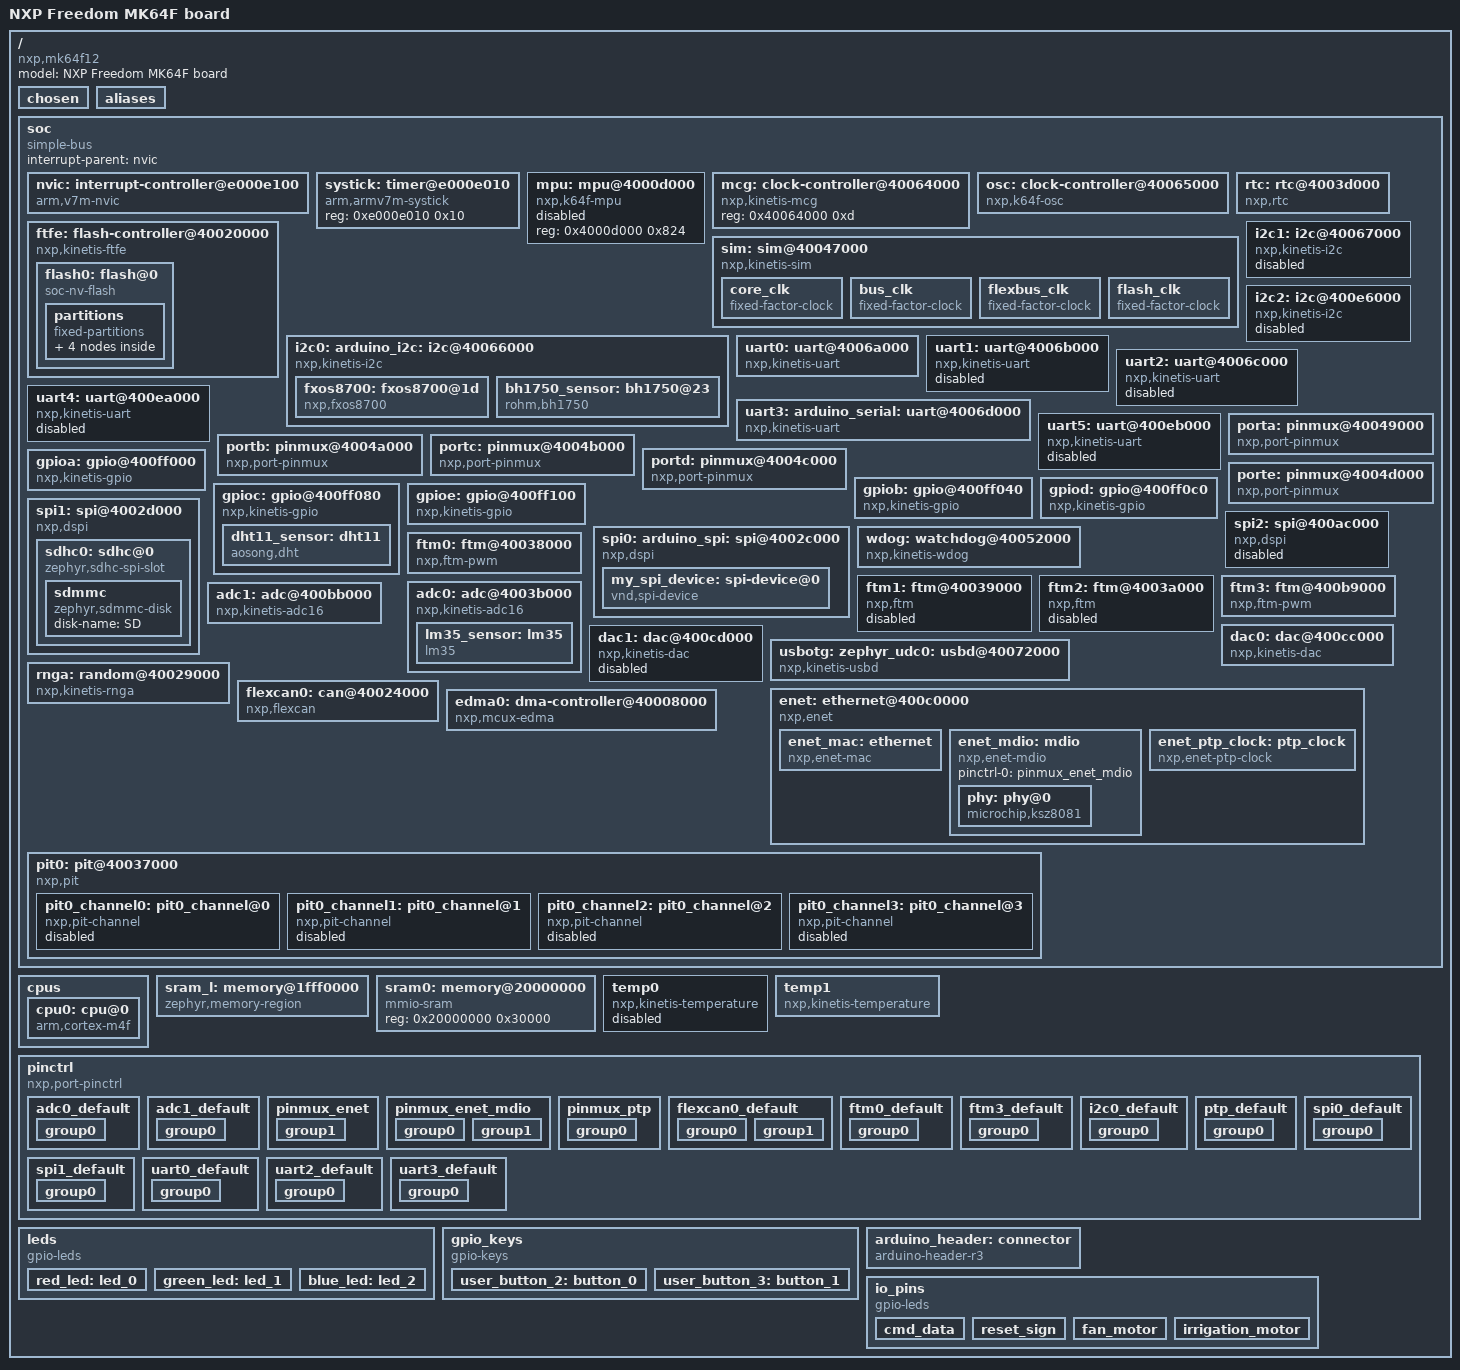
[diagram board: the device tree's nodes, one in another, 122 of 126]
/dts-v1/;

/* node '/' defined in zephyr\dts\common\skeleton.dtsi:9 */
/ {
	#address-cells = < 0x1 >;          /* in zephyr\dts\common\skeleton.dtsi:10 */
	#size-cells = < 0x1 >;             /* in zephyr\dts\common\skeleton.dtsi:11 */
	model = "NXP Freedom MK64F board"; /* in zephyr\boards\nxp\frdm_k64f\frdm_k64f.dts:10 */
	compatible = "nxp,mk64f12",
	             "nxp,k64f",
	             "nxp,k6x";            /* in zephyr\boards\nxp\frdm_k64f\frdm_k64f.dts:11 */

	/* node '/chosen' defined in zephyr\dts\common\skeleton.dtsi:12 */
	chosen {
		zephyr,entropy = &rnga;                   /* in zephyr\dts\arm\nxp\nxp_k6x.dtsi:17 */
		zephyr,flash-controller = &ftfe;          /* in zephyr\dts\arm\nxp\nxp_k6x.dtsi:18 */
		zephyr,sram = &sram0;                     /* in zephyr\boards\nxp\frdm_k64f\frdm_k64f.dts:25 */
		zephyr,flash = &flash0;                   /* in zephyr\boards\nxp\frdm_k64f\frdm_k64f.dts:26 */
		zephyr,code-partition = &slot0_partition; /* in zephyr\boards\nxp\frdm_k64f\frdm_k64f.dts:27 */
		zephyr,console = &uart0;                  /* in zephyr\boards\nxp\frdm_k64f\frdm_k64f.dts:28 */
		zephyr,shell-uart = &uart0;               /* in zephyr\boards\nxp\frdm_k64f\frdm_k64f.dts:29 */
		zephyr,uart-pipe = &uart0;                /* in zephyr\boards\nxp\frdm_k64f\frdm_k64f.dts:30 */
		zephyr,canbus = &flexcan0;                /* in zephyr\boards\nxp\frdm_k64f\frdm_k64f.dts:31 */
		zephyr,uart-mcumgr = &uart0;              /* in zephyr\boards\nxp\frdm_k64f\frdm_k64f.dts:32 */
	};

	/* node '/aliases' defined in zephyr\dts\common\skeleton.dtsi:13 */
	aliases {
		watchdog0 = &wdog;                       /* in zephyr\dts\arm\nxp\nxp_k6x.dtsi:13 */
		led0 = &green_led;                       /* in zephyr\boards\nxp\frdm_k64f\frdm_k64f.dts:14 */
		led1 = &blue_led;                        /* in zephyr\boards\nxp\frdm_k64f\frdm_k64f.dts:15 */
		led2 = &red_led;                         /* in zephyr\boards\nxp\frdm_k64f\frdm_k64f.dts:16 */
		sw0 = &user_button_3;                    /* in zephyr\boards\nxp\frdm_k64f\frdm_k64f.dts:17 */
		sw1 = &user_button_2;                    /* in zephyr\boards\nxp\frdm_k64f\frdm_k64f.dts:18 */
		magn0 = &fxos8700;                       /* in zephyr\boards\nxp\frdm_k64f\frdm_k64f.dts:19 */
		accel0 = &fxos8700;                      /* in zephyr\boards\nxp\frdm_k64f\frdm_k64f.dts:20 */
		mcuboot-button0 = &user_button_2;        /* in zephyr\boards\nxp\frdm_k64f\frdm_k64f.dts:21 */
		cmd-data = &cmd_data;                    /* in ..\nokia_lcd_zephyr\boards\frdm_k64f.overlay:4 */
		reset-pin = &reset_sign;                 /* in ..\nokia_lcd_zephyr\boards\frdm_k64f.overlay:5 */
		lm35 = &lm35_sensor;                     /* in ..\nokia_lcd_zephyr\boards\frdm_k64f.overlay:8 */
		bh1750 = &bh1750_sensor;                 /* in ..\nokia_lcd_zephyr\boards\frdm_k64f.overlay:9 */
		dht11 = &dht11_sensor;                   /* in ..\nokia_lcd_zephyr\boards\frdm_k64f.overlay:10 */
		fan-actuator = &fan_motor;               /* in ..\nokia_lcd_zephyr\boards\frdm_k64f.overlay:13 */
		irrigation-actuator = &irrigation_motor; /* in ..\nokia_lcd_zephyr\boards\frdm_k64f.overlay:14 */
	};

	/* node '/soc' defined in zephyr\dts\arm\armv7-m.dtsi:6 */
	soc {
		#address-cells = < 0x1 >;     /* in zephyr\dts\arm\armv7-m.dtsi:7 */
		#size-cells = < 0x1 >;        /* in zephyr\dts\arm\armv7-m.dtsi:8 */
		compatible = "simple-bus";    /* in zephyr\dts\arm\armv7-m.dtsi:9 */
		interrupt-parent = < &nvic >; /* in zephyr\dts\arm\armv7-m.dtsi:10 */
		ranges;                       /* in zephyr\dts\arm\armv7-m.dtsi:11 */

		/* node '/soc/interrupt-controller@e000e100' defined in zephyr\dts\arm\armv7-m.dtsi:13 */
		nvic: interrupt-controller@e000e100 {
			#address-cells = < 0x1 >;            /* in zephyr\dts\arm\armv7-m.dtsi:14 */
			compatible = "arm,v7m-nvic";         /* in zephyr\dts\arm\armv7-m.dtsi:15 */
			reg = < 0xe000e100 0xc00 >;          /* in zephyr\dts\arm\armv7-m.dtsi:16 */
			interrupt-controller;                /* in zephyr\dts\arm\armv7-m.dtsi:17 */
			#interrupt-cells = < 0x2 >;          /* in zephyr\dts\arm\armv7-m.dtsi:18 */
			arm,num-irq-priority-bits = < 0x4 >; /* in zephyr\dts\arm\nxp\nxp_k6x.dtsi:582 */
			phandle = < 0x1 >;                   /* in zephyr\dts\arm\armv7-m.dtsi:10 */
		};

		/* node '/soc/timer@e000e010' defined in zephyr\dts\arm\armv7-m.dtsi:21 */
		systick: timer@e000e010 {
			compatible = "arm,armv7m-systick"; /* in zephyr\dts\arm\armv7-m.dtsi:22 */
			reg = < 0xe000e010 0x10 >;         /* in zephyr\dts\arm\armv7-m.dtsi:23 */
		};

		/* node '/soc/mpu@4000d000' defined in zephyr\dts\arm\nxp\nxp_k6x.dtsi:83 */
		mpu: mpu@4000d000 {
			compatible = "nxp,k64f-mpu"; /* in zephyr\dts\arm\nxp\nxp_k6x.dtsi:84 */
			reg = < 0x4000d000 0x824 >;  /* in zephyr\dts\arm\nxp\nxp_k6x.dtsi:85 */
			status = "disabled";         /* in zephyr\dts\arm\nxp\nxp_k6x.dtsi:87 */
		};

		/* node '/soc/clock-controller@40064000' defined in zephyr\dts\arm\nxp\nxp_k6x.dtsi:90 */
		mcg: clock-controller@40064000 {
			compatible = "nxp,kinetis-mcg"; /* in zephyr\dts\arm\nxp\nxp_k6x.dtsi:91 */
			reg = < 0x40064000 0xd >;       /* in zephyr\dts\arm\nxp\nxp_k6x.dtsi:92 */
			#clock-cells = < 0x1 >;         /* in zephyr\dts\arm\nxp\nxp_k6x.dtsi:93 */
			phandle = < 0x2 >;              /* in zephyr\dts\arm\nxp\nxp_k6x.dtsi:119 */
		};

		/* node '/soc/clock-controller@40065000' defined in zephyr\dts\arm\nxp\nxp_k6x.dtsi:96 */
		osc: clock-controller@40065000 {
			compatible = "nxp,k64f-osc"; /* in zephyr\dts\arm\nxp\nxp_k6x.dtsi:97 */
			reg = < 0x40065000 0x4 >;    /* in zephyr\dts\arm\nxp\nxp_k6x.dtsi:98 */
			enable-external-reference;   /* in zephyr\dts\arm\nxp\nxp_k6x.dtsi:100 */
		};

		/* node '/soc/rtc@4003d000' defined in zephyr\dts\arm\nxp\nxp_k6x.dtsi:103 */
		rtc: rtc@4003d000 {
			compatible = "nxp,rtc";       /* in zephyr\dts\arm\nxp\nxp_k6x.dtsi:104 */
			reg = < 0x4003d000 0x1000 >;  /* in zephyr\dts\arm\nxp\nxp_k6x.dtsi:105 */
			interrupts = < 0x2e 0x0 >,
			             < 0x2f 0x0 >;    /* in zephyr\dts\arm\nxp\nxp_k6x.dtsi:106 */
			interrupt-names = "alarm",
			                  "seconds";  /* in zephyr\dts\arm\nxp\nxp_k6x.dtsi:107 */
			clock-frequency = < 0x8000 >; /* in zephyr\dts\arm\nxp\nxp_k6x.dtsi:108 */
			prescaler = < 0x8000 >;       /* in zephyr\dts\arm\nxp\nxp_k6x.dtsi:109 */
		};

		/* node '/soc/sim@40047000' defined in zephyr\dts\arm\nxp\nxp_k6x.dtsi:112 */
		sim: sim@40047000 {
			compatible = "nxp,kinetis-sim"; /* in zephyr\dts\arm\nxp\nxp_k6x.dtsi:113 */
			reg = < 0x40047000 0x1060 >;    /* in zephyr\dts\arm\nxp\nxp_k6x.dtsi:114 */
			#clock-cells = < 0x3 >;         /* in zephyr\dts\arm\nxp\nxp_k6x.dtsi:115 */
			pllfll-select = < 0x1 >;        /* in zephyr\boards\nxp\frdm_k64f\frdm_k64f.dts:99 */
			er32k-select = < 0x2 >;         /* in zephyr\boards\nxp\frdm_k64f\frdm_k64f.dts:100 */
			phandle = < 0x3 >;              /* in zephyr\dts\arm\nxp\nxp_k6x.dtsi:171 */

			/* node '/soc/sim@40047000/core_clk' defined in zephyr\dts\arm\nxp\nxp_k6x.dtsi:117 */
			core_clk {
				compatible = "fixed-factor-clock"; /* in zephyr\dts\arm\nxp\nxp_k6x.dtsi:118 */
				clocks = < &mcg 0x1 >;             /* in zephyr\dts\arm\nxp\nxp_k6x.dtsi:119 */
				clock-div = < 0x1 >;               /* in zephyr\dts\arm\nxp\nxp_k6x.dtsi:120 */
				#clock-cells = < 0x0 >;            /* in zephyr\dts\arm\nxp\nxp_k6x.dtsi:121 */
			};

			/* node '/soc/sim@40047000/bus_clk' defined in zephyr\dts\arm\nxp\nxp_k6x.dtsi:124 */
			bus_clk {
				compatible = "fixed-factor-clock"; /* in zephyr\dts\arm\nxp\nxp_k6x.dtsi:125 */
				clocks = < &mcg 0x1 >;             /* in zephyr\dts\arm\nxp\nxp_k6x.dtsi:126 */
				clock-div = < 0x2 >;               /* in zephyr\dts\arm\nxp\nxp_k6x.dtsi:127 */
				#clock-cells = < 0x0 >;            /* in zephyr\dts\arm\nxp\nxp_k6x.dtsi:128 */
			};

			/* node '/soc/sim@40047000/flexbus_clk' defined in zephyr\dts\arm\nxp\nxp_k6x.dtsi:131 */
			flexbus_clk {
				compatible = "fixed-factor-clock"; /* in zephyr\dts\arm\nxp\nxp_k6x.dtsi:132 */
				clocks = < &mcg 0x1 >;             /* in zephyr\dts\arm\nxp\nxp_k6x.dtsi:133 */
				clock-div = < 0x3 >;               /* in zephyr\dts\arm\nxp\nxp_k6x.dtsi:134 */
				#clock-cells = < 0x0 >;            /* in zephyr\dts\arm\nxp\nxp_k6x.dtsi:135 */
			};

			/* node '/soc/sim@40047000/flash_clk' defined in zephyr\dts\arm\nxp\nxp_k6x.dtsi:138 */
			flash_clk {
				compatible = "fixed-factor-clock"; /* in zephyr\dts\arm\nxp\nxp_k6x.dtsi:139 */
				clocks = < &mcg 0x1 >;             /* in zephyr\dts\arm\nxp\nxp_k6x.dtsi:140 */
				clock-div = < 0x5 >;               /* in zephyr\dts\arm\nxp\nxp_k6x.dtsi:141 */
				#clock-cells = < 0x0 >;            /* in zephyr\dts\arm\nxp\nxp_k6x.dtsi:142 */
			};
		};

		/* node '/soc/flash-controller@40020000' defined in zephyr\dts\arm\nxp\nxp_k6x.dtsi:146 */
		ftfe: flash-controller@40020000 {
			compatible = "nxp,kinetis-ftfe";      /* in zephyr\dts\arm\nxp\nxp_k6x.dtsi:147 */
			reg = < 0x40020000 0x18 >;            /* in zephyr\dts\arm\nxp\nxp_k6x.dtsi:148 */
			interrupts = < 0x12 0x0 >,
			             < 0x13 0x0 >;            /* in zephyr\dts\arm\nxp\nxp_k6x.dtsi:149 */
			interrupt-names = "command-complete",
			                  "read-collision";   /* in zephyr\dts\arm\nxp\nxp_k6x.dtsi:150 */
			status = "okay";                      /* in zephyr\dts\arm\nxp\nxp_k6x.dtsi:151 */
			#address-cells = < 0x1 >;             /* in zephyr\dts\arm\nxp\nxp_k6x.dtsi:153 */
			#size-cells = < 0x1 >;                /* in zephyr\dts\arm\nxp\nxp_k6x.dtsi:154 */

			/* node '/soc/flash-controller@40020000/flash@0' defined in zephyr\dts\arm\nxp\nxp_k6x.dtsi:156 */
			flash0: flash@0 {
				compatible = "soc-nv-flash";   /* in zephyr\dts\arm\nxp\nxp_k6x.dtsi:157 */
				reg = < 0x0 0x100000 >;        /* in zephyr\dts\arm\nxp\nxp_k6x.dtsi:158 */
				erase-block-size = < 0x1000 >; /* in zephyr\dts\arm\nxp\nxp_k6x.dtsi:159 */
				write-block-size = < 0x8 >;    /* in zephyr\dts\arm\nxp\nxp_k6x.dtsi:160 */

				/* node '/soc/flash-controller@40020000/flash@0/partitions' defined in zephyr\boards\nxp\frdm_k64f\frdm_k64f.dts:231 */
				partitions {
					compatible = "fixed-partitions"; /* in zephyr\boards\nxp\frdm_k64f\frdm_k64f.dts:232 */
					#address-cells = < 0x1 >;        /* in zephyr\boards\nxp\frdm_k64f\frdm_k64f.dts:233 */
					#size-cells = < 0x1 >;           /* in zephyr\boards\nxp\frdm_k64f\frdm_k64f.dts:234 */

					/* node '/soc/flash-controller@40020000/flash@0/partitions/partition@0' defined in zephyr\boards\nxp\frdm_k64f\frdm_k64f.dts:240 */
					boot_partition: partition@0 {
						label = "mcuboot";     /* in zephyr\boards\nxp\frdm_k64f\frdm_k64f.dts:241 */
						reg = < 0x0 0x10000 >; /* in zephyr\boards\nxp\frdm_k64f\frdm_k64f.dts:242 */
						read-only;             /* in zephyr\boards\nxp\frdm_k64f\frdm_k64f.dts:243 */
					};

					/* node '/soc/flash-controller@40020000/flash@0/partitions/partition@10000' defined in zephyr\boards\nxp\frdm_k64f\frdm_k64f.dts:245 */
					slot0_partition: partition@10000 {
						label = "image-0";         /* in zephyr\boards\nxp\frdm_k64f\frdm_k64f.dts:246 */
						reg = < 0x10000 0x69000 >; /* in zephyr\boards\nxp\frdm_k64f\frdm_k64f.dts:247 */
					};

					/* node '/soc/flash-controller@40020000/flash@0/partitions/partition@79000' defined in zephyr\boards\nxp\frdm_k64f\frdm_k64f.dts:249 */
					slot1_partition: partition@79000 {
						label = "image-1";         /* in zephyr\boards\nxp\frdm_k64f\frdm_k64f.dts:250 */
						reg = < 0x79000 0x69000 >; /* in zephyr\boards\nxp\frdm_k64f\frdm_k64f.dts:251 */
					};

					/* node '/soc/flash-controller@40020000/flash@0/partitions/partition@e2000' defined in zephyr\boards\nxp\frdm_k64f\frdm_k64f.dts:253 */
					storage_partition: partition@e2000 {
						label = "storage";         /* in zephyr\boards\nxp\frdm_k64f\frdm_k64f.dts:254 */
						reg = < 0xe2000 0x1e000 >; /* in zephyr\boards\nxp\frdm_k64f\frdm_k64f.dts:255 */
					};
				};
			};
		};

		/* node '/soc/i2c@40066000' defined in zephyr\dts\arm\nxp\nxp_k6x.dtsi:164 */
		i2c0: arduino_i2c: i2c@40066000 {
			compatible = "nxp,kinetis-i2c";   /* in zephyr\dts\arm\nxp\nxp_k6x.dtsi:165 */
			clock-frequency = < 0x186a0 >;    /* in zephyr\dts\arm\nxp\nxp_k6x.dtsi:166 */
			#address-cells = < 0x1 >;         /* in zephyr\dts\arm\nxp\nxp_k6x.dtsi:167 */
			#size-cells = < 0x0 >;            /* in zephyr\dts\arm\nxp\nxp_k6x.dtsi:168 */
			reg = < 0x40066000 0x1000 >;      /* in zephyr\dts\arm\nxp\nxp_k6x.dtsi:169 */
			interrupts = < 0x18 0x0 >;        /* in zephyr\dts\arm\nxp\nxp_k6x.dtsi:170 */
			clocks = < &sim 0x2 0x1034 0x6 >; /* in zephyr\dts\arm\nxp\nxp_k6x.dtsi:171 */
			status = "okay";                  /* in ..\nokia_lcd_zephyr\boards\frdm_k64f.overlay:81 */
			pinctrl-0 = < &i2c0_default >;    /* in ..\nokia_lcd_zephyr\boards\frdm_k64f.overlay:82 */
			pinctrl-names = "default";        /* in ..\nokia_lcd_zephyr\boards\frdm_k64f.overlay:83 */

			/* node '/soc/i2c@40066000/fxos8700@1d' defined in zephyr\boards\nxp\frdm_k64f\frdm_k64f.dts:140 */
			fxos8700: fxos8700@1d {
				compatible = "nxp,fxos8700";     /* in zephyr\boards\nxp\frdm_k64f\frdm_k64f.dts:141 */
				reg = < 0x1d >;                  /* in zephyr\boards\nxp\frdm_k64f\frdm_k64f.dts:142 */
				int1-gpios = < &gpioc 0x6 0x1 >; /* in zephyr\boards\nxp\frdm_k64f\frdm_k64f.dts:143 */
				int2-gpios = < &gpioc 0xd 0x1 >; /* in zephyr\boards\nxp\frdm_k64f\frdm_k64f.dts:144 */
			};

			/* node '/soc/i2c@40066000/bh1750@23' defined in ..\nokia_lcd_zephyr\boards\frdm_k64f.overlay:85 */
			bh1750_sensor: bh1750@23 {
				compatible = "rohm,bh1750";    /* in ..\nokia_lcd_zephyr\boards\frdm_k64f.overlay:86 */
				reg = < 0x23 >;                /* in ..\nokia_lcd_zephyr\boards\frdm_k64f.overlay:87 */
				status = "okay";               /* in ..\nokia_lcd_zephyr\boards\frdm_k64f.overlay:88 */
				label = "BH1750 Light Sensor"; /* in ..\nokia_lcd_zephyr\boards\frdm_k64f.overlay:89 */
			};
		};

		/* node '/soc/i2c@40067000' defined in zephyr\dts\arm\nxp\nxp_k6x.dtsi:175 */
		i2c1: i2c@40067000 {
			compatible = "nxp,kinetis-i2c";   /* in zephyr\dts\arm\nxp\nxp_k6x.dtsi:176 */
			clock-frequency = < 0x186a0 >;    /* in zephyr\dts\arm\nxp\nxp_k6x.dtsi:177 */
			#address-cells = < 0x1 >;         /* in zephyr\dts\arm\nxp\nxp_k6x.dtsi:178 */
			#size-cells = < 0x0 >;            /* in zephyr\dts\arm\nxp\nxp_k6x.dtsi:179 */
			reg = < 0x40067000 0x1000 >;      /* in zephyr\dts\arm\nxp\nxp_k6x.dtsi:180 */
			interrupts = < 0x19 0x0 >;        /* in zephyr\dts\arm\nxp\nxp_k6x.dtsi:181 */
			clocks = < &sim 0x2 0x1034 0x7 >; /* in zephyr\dts\arm\nxp\nxp_k6x.dtsi:182 */
			status = "disabled";              /* in zephyr\dts\arm\nxp\nxp_k6x.dtsi:183 */
		};

		/* node '/soc/i2c@400e6000' defined in zephyr\dts\arm\nxp\nxp_k6x.dtsi:186 */
		i2c2: i2c@400e6000 {
			compatible = "nxp,kinetis-i2c";   /* in zephyr\dts\arm\nxp\nxp_k6x.dtsi:187 */
			clock-frequency = < 0x186a0 >;    /* in zephyr\dts\arm\nxp\nxp_k6x.dtsi:188 */
			#address-cells = < 0x1 >;         /* in zephyr\dts\arm\nxp\nxp_k6x.dtsi:189 */
			#size-cells = < 0x0 >;            /* in zephyr\dts\arm\nxp\nxp_k6x.dtsi:190 */
			reg = < 0x400e6000 0x1000 >;      /* in zephyr\dts\arm\nxp\nxp_k6x.dtsi:191 */
			interrupts = < 0x4a 0x0 >;        /* in zephyr\dts\arm\nxp\nxp_k6x.dtsi:192 */
			clocks = < &sim 0x2 0x1028 0x6 >; /* in zephyr\dts\arm\nxp\nxp_k6x.dtsi:193 */
			status = "disabled";              /* in zephyr\dts\arm\nxp\nxp_k6x.dtsi:194 */
		};

		/* node '/soc/uart@4006a000' defined in zephyr\dts\arm\nxp\nxp_k6x.dtsi:197 */
		uart0: uart@4006a000 {
			compatible = "nxp,kinetis-uart";  /* in zephyr\dts\arm\nxp\nxp_k6x.dtsi:198 */
			reg = < 0x4006a000 0x1000 >;      /* in zephyr\dts\arm\nxp\nxp_k6x.dtsi:199 */
			interrupts = < 0x1f 0x0 >,
			             < 0x20 0x0 >;        /* in zephyr\dts\arm\nxp\nxp_k6x.dtsi:200 */
			interrupt-names = "status",
			                  "error";        /* in zephyr\dts\arm\nxp\nxp_k6x.dtsi:201 */
			clocks = < &sim 0x0 0x1034 0xa >; /* in zephyr\dts\arm\nxp\nxp_k6x.dtsi:202 */
			status = "okay";                  /* in zephyr\boards\nxp\frdm_k64f\frdm_k64f.dts:192 */
			current-speed = < 0x1c200 >;      /* in zephyr\boards\nxp\frdm_k64f\frdm_k64f.dts:193 */
			pinctrl-0 = < &uart0_default >;   /* in zephyr\boards\nxp\frdm_k64f\frdm_k64f.dts:194 */
			pinctrl-names = "default";        /* in zephyr\boards\nxp\frdm_k64f\frdm_k64f.dts:195 */
		};

		/* node '/soc/uart@4006b000' defined in zephyr\dts\arm\nxp\nxp_k6x.dtsi:207 */
		uart1: uart@4006b000 {
			compatible = "nxp,kinetis-uart";  /* in zephyr\dts\arm\nxp\nxp_k6x.dtsi:208 */
			reg = < 0x4006b000 0x1000 >;      /* in zephyr\dts\arm\nxp\nxp_k6x.dtsi:209 */
			interrupts = < 0x21 0x0 >,
			             < 0x22 0x0 >;        /* in zephyr\dts\arm\nxp\nxp_k6x.dtsi:210 */
			interrupt-names = "status",
			                  "error";        /* in zephyr\dts\arm\nxp\nxp_k6x.dtsi:211 */
			clocks = < &sim 0x0 0x1034 0xb >; /* in zephyr\dts\arm\nxp\nxp_k6x.dtsi:212 */
			status = "disabled";              /* in zephyr\dts\arm\nxp\nxp_k6x.dtsi:214 */
		};

		/* node '/soc/uart@4006c000' defined in zephyr\dts\arm\nxp\nxp_k6x.dtsi:217 */
		uart2: uart@4006c000 {
			compatible = "nxp,kinetis-uart";  /* in zephyr\dts\arm\nxp\nxp_k6x.dtsi:218 */
			reg = < 0x4006c000 0x1000 >;      /* in zephyr\dts\arm\nxp\nxp_k6x.dtsi:219 */
			interrupts = < 0x23 0x0 >,
			             < 0x24 0x0 >;        /* in zephyr\dts\arm\nxp\nxp_k6x.dtsi:220 */
			interrupt-names = "status",
			                  "error";        /* in zephyr\dts\arm\nxp\nxp_k6x.dtsi:221 */
			clocks = < &sim 0x2 0x1034 0xc >; /* in zephyr\dts\arm\nxp\nxp_k6x.dtsi:222 */
			status = "disabled";              /* in zephyr\dts\arm\nxp\nxp_k6x.dtsi:224 */
			pinctrl-0 = < &uart2_default >;   /* in zephyr\boards\nxp\frdm_k64f\frdm_k64f.dts:199 */
			pinctrl-names = "default";        /* in zephyr\boards\nxp\frdm_k64f\frdm_k64f.dts:200 */
		};

		/* node '/soc/uart@4006d000' defined in zephyr\dts\arm\nxp\nxp_k6x.dtsi:227 */
		uart3: arduino_serial: uart@4006d000 {
			compatible = "nxp,kinetis-uart";  /* in zephyr\dts\arm\nxp\nxp_k6x.dtsi:228 */
			reg = < 0x4006d000 0x1000 >;      /* in zephyr\dts\arm\nxp\nxp_k6x.dtsi:229 */
			interrupts = < 0x25 0x0 >,
			             < 0x26 0x0 >;        /* in zephyr\dts\arm\nxp\nxp_k6x.dtsi:230 */
			interrupt-names = "status",
			                  "error";        /* in zephyr\dts\arm\nxp\nxp_k6x.dtsi:231 */
			clocks = < &sim 0x2 0x1034 0xd >; /* in zephyr\dts\arm\nxp\nxp_k6x.dtsi:232 */
			status = "okay";                  /* in ..\nokia_lcd_zephyr\boards\frdm_k64f.overlay:111 */
			current-speed = < 0x2580 >;       /* in ..\nokia_lcd_zephyr\boards\frdm_k64f.overlay:112 */
			pinctrl-0 = < &uart3_default >;   /* in ..\nokia_lcd_zephyr\boards\frdm_k64f.overlay:113 */
			pinctrl-names = "default";        /* in ..\nokia_lcd_zephyr\boards\frdm_k64f.overlay:114 */
		};

		/* node '/soc/uart@400ea000' defined in zephyr\dts\arm\nxp\nxp_k6x.dtsi:237 */
		uart4: uart@400ea000 {
			compatible = "nxp,kinetis-uart";  /* in zephyr\dts\arm\nxp\nxp_k6x.dtsi:238 */
			reg = < 0x400ea000 0x1000 >;      /* in zephyr\dts\arm\nxp\nxp_k6x.dtsi:239 */
			interrupts = < 0x42 0x0 >,
			             < 0x43 0x0 >;        /* in zephyr\dts\arm\nxp\nxp_k6x.dtsi:240 */
			interrupt-names = "status",
			                  "error";        /* in zephyr\dts\arm\nxp\nxp_k6x.dtsi:241 */
			clocks = < &sim 0x2 0x1028 0xa >; /* in zephyr\dts\arm\nxp\nxp_k6x.dtsi:242 */
			status = "disabled";              /* in zephyr\dts\arm\nxp\nxp_k6x.dtsi:244 */
		};

		/* node '/soc/uart@400eb000' defined in zephyr\dts\arm\nxp\nxp_k6x.dtsi:247 */
		uart5: uart@400eb000 {
			compatible = "nxp,kinetis-uart";  /* in zephyr\dts\arm\nxp\nxp_k6x.dtsi:248 */
			reg = < 0x400eb000 0x1000 >;      /* in zephyr\dts\arm\nxp\nxp_k6x.dtsi:249 */
			interrupts = < 0x44 0x0 >,
			             < 0x45 0x0 >;        /* in zephyr\dts\arm\nxp\nxp_k6x.dtsi:250 */
			interrupt-names = "status",
			                  "error";        /* in zephyr\dts\arm\nxp\nxp_k6x.dtsi:251 */
			clocks = < &sim 0x2 0x1028 0xb >; /* in zephyr\dts\arm\nxp\nxp_k6x.dtsi:252 */
			status = "disabled";              /* in zephyr\dts\arm\nxp\nxp_k6x.dtsi:254 */
		};

		/* node '/soc/pinmux@40049000' defined in zephyr\dts\arm\nxp\nxp_k6x.dtsi:257 */
		porta: pinmux@40049000 {
			compatible = "nxp,port-pinmux";   /* in zephyr\dts\arm\nxp\nxp_k6x.dtsi:258 */
			reg = < 0x40049000 0xd0 >;        /* in zephyr\dts\arm\nxp\nxp_k6x.dtsi:259 */
			clocks = < &sim 0x2 0x1038 0x9 >; /* in zephyr\dts\arm\nxp\nxp_k6x.dtsi:260 */
			phandle = < 0x9 >;                /* in zephyr\dts\arm\nxp\nxp_k6x.dtsi:294 */
		};

		/* node '/soc/pinmux@4004a000' defined in zephyr\dts\arm\nxp\nxp_k6x.dtsi:263 */
		portb: pinmux@4004a000 {
			compatible = "nxp,port-pinmux";   /* in zephyr\dts\arm\nxp\nxp_k6x.dtsi:264 */
			reg = < 0x4004a000 0xd0 >;        /* in zephyr\dts\arm\nxp\nxp_k6x.dtsi:265 */
			clocks = < &sim 0x2 0x1038 0xa >; /* in zephyr\dts\arm\nxp\nxp_k6x.dtsi:266 */
			phandle = < 0xa >;                /* in zephyr\dts\arm\nxp\nxp_k6x.dtsi:304 */
		};

		/* node '/soc/pinmux@4004b000' defined in zephyr\dts\arm\nxp\nxp_k6x.dtsi:269 */
		portc: pinmux@4004b000 {
			compatible = "nxp,port-pinmux";   /* in zephyr\dts\arm\nxp\nxp_k6x.dtsi:270 */
			reg = < 0x4004b000 0xd0 >;        /* in zephyr\dts\arm\nxp\nxp_k6x.dtsi:271 */
			clocks = < &sim 0x2 0x1038 0xb >; /* in zephyr\dts\arm\nxp\nxp_k6x.dtsi:272 */
			phandle = < 0xb >;                /* in zephyr\dts\arm\nxp\nxp_k6x.dtsi:314 */
		};

		/* node '/soc/pinmux@4004c000' defined in zephyr\dts\arm\nxp\nxp_k6x.dtsi:275 */
		portd: pinmux@4004c000 {
			compatible = "nxp,port-pinmux";   /* in zephyr\dts\arm\nxp\nxp_k6x.dtsi:276 */
			reg = < 0x4004c000 0xd0 >;        /* in zephyr\dts\arm\nxp\nxp_k6x.dtsi:277 */
			clocks = < &sim 0x2 0x1038 0xc >; /* in zephyr\dts\arm\nxp\nxp_k6x.dtsi:278 */
			phandle = < 0xc >;                /* in zephyr\dts\arm\nxp\nxp_k6x.dtsi:324 */
		};

		/* node '/soc/pinmux@4004d000' defined in zephyr\dts\arm\nxp\nxp_k6x.dtsi:281 */
		porte: pinmux@4004d000 {
			compatible = "nxp,port-pinmux";   /* in zephyr\dts\arm\nxp\nxp_k6x.dtsi:282 */
			reg = < 0x4004d000 0xd0 >;        /* in zephyr\dts\arm\nxp\nxp_k6x.dtsi:283 */
			clocks = < &sim 0x2 0x1038 0xd >; /* in zephyr\dts\arm\nxp\nxp_k6x.dtsi:284 */
			phandle = < 0xd >;                /* in zephyr\dts\arm\nxp\nxp_k6x.dtsi:334 */
		};

		/* node '/soc/gpio@400ff000' defined in zephyr\dts\arm\nxp\nxp_k6x.dtsi:287 */
		gpioa: gpio@400ff000 {
			compatible = "nxp,kinetis-gpio"; /* in zephyr\dts\arm\nxp\nxp_k6x.dtsi:288 */
			reg = < 0x400ff000 0x40 >;       /* in zephyr\dts\arm\nxp\nxp_k6x.dtsi:290 */
			interrupts = < 0x3b 0x2 >;       /* in zephyr\dts\arm\nxp\nxp_k6x.dtsi:291 */
			gpio-controller;                 /* in zephyr\dts\arm\nxp\nxp_k6x.dtsi:292 */
			#gpio-cells = < 0x2 >;           /* in zephyr\dts\arm\nxp\nxp_k6x.dtsi:293 */
			nxp,kinetis-port = < &porta >;   /* in zephyr\dts\arm\nxp\nxp_k6x.dtsi:294 */
			status = "okay";                 /* in zephyr\boards\nxp\frdm_k64f\frdm_k64f.dts:210 */
			phandle = < 0x20 >;              /* in zephyr\boards\nxp\frdm_k64f\frdm_k64f.dts:60 */
		};

		/* node '/soc/gpio@400ff040' defined in zephyr\dts\arm\nxp\nxp_k6x.dtsi:297 */
		gpiob: gpio@400ff040 {
			compatible = "nxp,kinetis-gpio"; /* in zephyr\dts\arm\nxp\nxp_k6x.dtsi:298 */
			reg = < 0x400ff040 0x40 >;       /* in zephyr\dts\arm\nxp\nxp_k6x.dtsi:300 */
			interrupts = < 0x3c 0x2 >;       /* in zephyr\dts\arm\nxp\nxp_k6x.dtsi:301 */
			gpio-controller;                 /* in zephyr\dts\arm\nxp\nxp_k6x.dtsi:302 */
			#gpio-cells = < 0x2 >;           /* in zephyr\dts\arm\nxp\nxp_k6x.dtsi:303 */
			nxp,kinetis-port = < &portb >;   /* in zephyr\dts\arm\nxp\nxp_k6x.dtsi:304 */
			status = "okay";                 /* in zephyr\boards\nxp\frdm_k64f\frdm_k64f.dts:214 */
			phandle = < 0x1f >;              /* in zephyr\boards\nxp\frdm_k64f\frdm_k64f.dts:38 */
		};

		/* node '/soc/gpio@400ff080' defined in zephyr\dts\arm\nxp\nxp_k6x.dtsi:307 */
		gpioc: gpio@400ff080 {
			compatible = "nxp,kinetis-gpio"; /* in zephyr\dts\arm\nxp\nxp_k6x.dtsi:308 */
			reg = < 0x400ff080 0x40 >;       /* in zephyr\dts\arm\nxp\nxp_k6x.dtsi:310 */
			interrupts = < 0x3d 0x2 >;       /* in zephyr\dts\arm\nxp\nxp_k6x.dtsi:311 */
			gpio-controller;                 /* in zephyr\dts\arm\nxp\nxp_k6x.dtsi:312 */
			#gpio-cells = < 0x2 >;           /* in zephyr\dts\arm\nxp\nxp_k6x.dtsi:313 */
			nxp,kinetis-port = < &portc >;   /* in zephyr\dts\arm\nxp\nxp_k6x.dtsi:314 */
			status = "okay";                 /* in ..\nokia_lcd_zephyr\boards\frdm_k64f.overlay:96 */
			phandle = < 0x5 >;               /* in zephyr\boards\nxp\frdm_k64f\frdm_k64f.dts:143 */

			/* node '/soc/gpio@400ff080/dht11' defined in ..\nokia_lcd_zephyr\boards\frdm_k64f.overlay:98 */
			dht11_sensor: dht11 {
				compatible = "aosong,dht";       /* in ..\nokia_lcd_zephyr\boards\frdm_k64f.overlay:99 */
				dio-gpios = < &gpioc 0x3 0x11 >; /* in ..\nokia_lcd_zephyr\boards\frdm_k64f.overlay:102 */
				status = "okay";                 /* in ..\nokia_lcd_zephyr\boards\frdm_k64f.overlay:105 */
				label = "DHT11 Humidity Sensor"; /* in ..\nokia_lcd_zephyr\boards\frdm_k64f.overlay:106 */
			};
		};

		/* node '/soc/gpio@400ff0c0' defined in zephyr\dts\arm\nxp\nxp_k6x.dtsi:317 */
		gpiod: gpio@400ff0c0 {
			compatible = "nxp,kinetis-gpio"; /* in zephyr\dts\arm\nxp\nxp_k6x.dtsi:318 */
			reg = < 0x400ff0c0 0x40 >;       /* in zephyr\dts\arm\nxp\nxp_k6x.dtsi:320 */
			interrupts = < 0x3e 0x2 >;       /* in zephyr\dts\arm\nxp\nxp_k6x.dtsi:321 */
			gpio-controller;                 /* in zephyr\dts\arm\nxp\nxp_k6x.dtsi:322 */
			#gpio-cells = < 0x2 >;           /* in zephyr\dts\arm\nxp\nxp_k6x.dtsi:323 */
			nxp,kinetis-port = < &portd >;   /* in zephyr\dts\arm\nxp\nxp_k6x.dtsi:324 */
			status = "okay";                 /* in zephyr\boards\nxp\frdm_k64f\frdm_k64f.dts:222 */
			phandle = < 0x21 >;              /* in zephyr\boards\nxp\frdm_k64f\frdm_k64f.dts:70 */
		};

		/* node '/soc/gpio@400ff100' defined in zephyr\dts\arm\nxp\nxp_k6x.dtsi:327 */
		gpioe: gpio@400ff100 {
			compatible = "nxp,kinetis-gpio"; /* in zephyr\dts\arm\nxp\nxp_k6x.dtsi:328 */
			reg = < 0x400ff100 0x40 >;       /* in zephyr\dts\arm\nxp\nxp_k6x.dtsi:330 */
			interrupts = < 0x3f 0x2 >;       /* in zephyr\dts\arm\nxp\nxp_k6x.dtsi:331 */
			gpio-controller;                 /* in zephyr\dts\arm\nxp\nxp_k6x.dtsi:332 */
			#gpio-cells = < 0x2 >;           /* in zephyr\dts\arm\nxp\nxp_k6x.dtsi:333 */
			nxp,kinetis-port = < &porte >;   /* in zephyr\dts\arm\nxp\nxp_k6x.dtsi:334 */
			status = "okay";                 /* in zephyr\boards\nxp\frdm_k64f\frdm_k64f.dts:226 */
			phandle = < 0x11 >;              /* in zephyr\boards\nxp\frdm_k64f\frdm_k64f.dts:158 */
		};

		/* node '/soc/spi@4002c000' defined in zephyr\dts\arm\nxp\nxp_k6x.dtsi:337 */
		spi0: arduino_spi: spi@4002c000 {
			compatible = "nxp,dspi";          /* in zephyr\dts\arm\nxp\nxp_k6x.dtsi:338 */
			reg = < 0x4002c000 0x88 >;        /* in zephyr\dts\arm\nxp\nxp_k6x.dtsi:339 */
			interrupts = < 0x1a 0x3 >;        /* in zephyr\dts\arm\nxp\nxp_k6x.dtsi:340 */
			dmas = < &edma0 0x0 0xe >,
			       < &edma0 0x0 0xf >;        /* in zephyr\dts\arm\nxp\nxp_k6x.dtsi:341 */
			dma-names = "rx",
			            "tx";                 /* in zephyr\dts\arm\nxp\nxp_k6x.dtsi:342 */
			rx-fifo-size = < 0x4 >;           /* in zephyr\dts\arm\nxp\nxp_k6x.dtsi:343 */
			tx-fifo-size = < 0x4 >;           /* in zephyr\dts\arm\nxp\nxp_k6x.dtsi:344 */
			clocks = < &sim 0x2 0x103c 0xc >; /* in zephyr\dts\arm\nxp\nxp_k6x.dtsi:345 */
			#address-cells = < 0x1 >;         /* in zephyr\dts\arm\nxp\nxp_k6x.dtsi:346 */
			#size-cells = < 0x0 >;            /* in zephyr\dts\arm\nxp\nxp_k6x.dtsi:347 */
			status = "okay";                  /* in ..\nokia_lcd_zephyr\boards\frdm_k64f.overlay:47 */
			pinctrl-0 = < &spi0_default >;    /* in ..\nokia_lcd_zephyr\boards\frdm_k64f.overlay:48 */
			pinctrl-names = "default";        /* in ..\nokia_lcd_zephyr\boards\frdm_k64f.overlay:49 */

			/* node '/soc/spi@4002c000/spi-device@0' defined in ..\nokia_lcd_zephyr\boards\frdm_k64f.overlay:51 */
			my_spi_device: spi-device@0 {
				compatible = "vnd,spi-device";   /* in ..\nokia_lcd_zephyr\boards\frdm_k64f.overlay:52 */
				reg = < 0x0 >;                   /* in ..\nokia_lcd_zephyr\boards\frdm_k64f.overlay:53 */
				spi-max-frequency = < 0xf4240 >; /* in ..\nokia_lcd_zephyr\boards\frdm_k64f.overlay:54 */
			};
		};

		/* node '/soc/spi@4002d000' defined in zephyr\dts\arm\nxp\nxp_k6x.dtsi:351 */
		spi1: spi@4002d000 {
			compatible = "nxp,dspi";          /* in zephyr\dts\arm\nxp\nxp_k6x.dtsi:352 */
			reg = < 0x4002d000 0x88 >;        /* in zephyr\dts\arm\nxp\nxp_k6x.dtsi:353 */
			interrupts = < 0x1b 0x3 >;        /* in zephyr\dts\arm\nxp\nxp_k6x.dtsi:354 */
			dmas = < &edma0 0x0 0x10 >,
			       < &edma0 0x0 0x10 >;       /* in zephyr\dts\arm\nxp\nxp_k6x.dtsi:355 */
			dma-names = "rx",
			            "tx";                 /* in zephyr\dts\arm\nxp\nxp_k6x.dtsi:356 */
			rx-fifo-size = < 0x1 >;           /* in zephyr\dts\arm\nxp\nxp_k6x.dtsi:357 */
			tx-fifo-size = < 0x1 >;           /* in zephyr\dts\arm\nxp\nxp_k6x.dtsi:358 */
			nxp,rx-tx-chn-share;              /* in zephyr\dts\arm\nxp\nxp_k6x.dtsi:359 */
			clocks = < &sim 0x2 0x103c 0xd >; /* in zephyr\dts\arm\nxp\nxp_k6x.dtsi:360 */
			#address-cells = < 0x1 >;         /* in zephyr\dts\arm\nxp\nxp_k6x.dtsi:361 */
			#size-cells = < 0x0 >;            /* in zephyr\dts\arm\nxp\nxp_k6x.dtsi:362 */
			status = "okay";                  /* in zephyr\boards\nxp\frdm_k64f\frdm_k64f.dts:155 */
			pinctrl-0 = < &spi1_default >;    /* in zephyr\boards\nxp\frdm_k64f\frdm_k64f.dts:156 */
			pinctrl-names = "default";        /* in zephyr\boards\nxp\frdm_k64f\frdm_k64f.dts:157 */
			cs-gpios = < &gpioe 0x4 0x1 >;    /* in zephyr\boards\nxp\frdm_k64f\frdm_k64f.dts:158 */

			/* node '/soc/spi@4002d000/sdhc@0' defined in zephyr\boards\nxp\frdm_k64f\frdm_k64f.dts:160 */
			sdhc0: sdhc@0 {
				compatible = "zephyr,sdhc-spi-slot"; /* in zephyr\boards\nxp\frdm_k64f\frdm_k64f.dts:161 */
				reg = < 0x0 >;                       /* in zephyr\boards\nxp\frdm_k64f\frdm_k64f.dts:162 */
				status = "okay";                     /* in zephyr\boards\nxp\frdm_k64f\frdm_k64f.dts:163 */
				spi-max-frequency = < 0x16e3600 >;   /* in zephyr\boards\nxp\frdm_k64f\frdm_k64f.dts:169 */

				/* node '/soc/spi@4002d000/sdhc@0/sdmmc' defined in zephyr\boards\nxp\frdm_k64f\frdm_k64f.dts:164 */
				sdmmc {
					compatible = "zephyr,sdmmc-disk"; /* in zephyr\boards\nxp\frdm_k64f\frdm_k64f.dts:165 */
					disk-name = "SD";                 /* in zephyr\boards\nxp\frdm_k64f\frdm_k64f.dts:166 */
					status = "okay";                  /* in zephyr\boards\nxp\frdm_k64f\frdm_k64f.dts:167 */
				};
			};
		};

		/* node '/soc/spi@400ac000' defined in zephyr\dts\arm\nxp\nxp_k6x.dtsi:366 */
		spi2: spi@400ac000 {
			compatible = "nxp,dspi";          /* in zephyr\dts\arm\nxp\nxp_k6x.dtsi:367 */
			reg = < 0x400ac000 0x88 >;        /* in zephyr\dts\arm\nxp\nxp_k6x.dtsi:368 */
			interrupts = < 0x41 0x3 >;        /* in zephyr\dts\arm\nxp\nxp_k6x.dtsi:369 */
			dmas = < &edma0 0x0 0x26 >,
			       < &edma0 0x0 0x27 >;       /* in zephyr\dts\arm\nxp\nxp_k6x.dtsi:370 */
			dma-names = "rx",
			            "tx";                 /* in zephyr\dts\arm\nxp\nxp_k6x.dtsi:371 */
			rx-fifo-size = < 0x1 >;           /* in zephyr\dts\arm\nxp\nxp_k6x.dtsi:372 */
			tx-fifo-size = < 0x1 >;           /* in zephyr\dts\arm\nxp\nxp_k6x.dtsi:373 */
			nxp,rx-tx-chn-share;              /* in zephyr\dts\arm\nxp\nxp_k6x.dtsi:374 */
			clocks = < &sim 0x2 0x1030 0xc >; /* in zephyr\dts\arm\nxp\nxp_k6x.dtsi:375 */
			#address-cells = < 0x1 >;         /* in zephyr\dts\arm\nxp\nxp_k6x.dtsi:376 */
			#size-cells = < 0x0 >;            /* in zephyr\dts\arm\nxp\nxp_k6x.dtsi:377 */
			status = "disabled";              /* in zephyr\dts\arm\nxp\nxp_k6x.dtsi:378 */
		};

		/* node '/soc/watchdog@40052000' defined in zephyr\dts\arm\nxp\nxp_k6x.dtsi:381 */
		wdog: watchdog@40052000 {
			compatible = "nxp,kinetis-wdog"; /* in zephyr\dts\arm\nxp\nxp_k6x.dtsi:382 */
			reg = < 0x40052000 0x10 >;       /* in zephyr\dts\arm\nxp\nxp_k6x.dtsi:383 */
			interrupts = < 0x16 0x0 >;       /* in zephyr\dts\arm\nxp\nxp_k6x.dtsi:384 */
			clocks = < &sim 0x13 0x0 0x0 >;  /* in zephyr\dts\arm\nxp\nxp_k6x.dtsi:385 */
		};

		/* node '/soc/ftm@40038000' defined in zephyr\dts\arm\nxp\nxp_k6x.dtsi:388 */
		ftm0: ftm@40038000 {
			reg = < 0x40038000 0x98 >;     /* in zephyr\dts\arm\nxp\nxp_k6x.dtsi:390 */
			interrupts = < 0x2a 0x0 >;     /* in zephyr\dts\arm\nxp\nxp_k6x.dtsi:391 */
			clocks = < &mcg 0x0 >;         /* in zephyr\dts\arm\nxp\nxp_k6x.dtsi:392 */
			prescaler = < 0x10 >;          /* in zephyr\dts\arm\nxp\nxp_k6x.dtsi:393 */
			status = "okay";               /* in zephyr\boards\nxp\frdm_k64f\frdm_k64f.dts:174 */
			compatible = "nxp,ftm-pwm";    /* in zephyr\boards\nxp\frdm_k64f\frdm_k64f.dts:175 */
			#pwm-cells = < 0x3 >;          /* in zephyr\boards\nxp\frdm_k64f\frdm_k64f.dts:176 */
			pinctrl-0 = < &ftm0_default >; /* in zephyr\boards\nxp\frdm_k64f\frdm_k64f.dts:177 */
			pinctrl-names = "default";     /* in zephyr\boards\nxp\frdm_k64f\frdm_k64f.dts:178 */
			clock-source = "fixed";        /* in zephyr\boards\nxp\frdm_k64f\frdm_k64f.dts:179 */
		};

		/* node '/soc/ftm@40039000' defined in zephyr\dts\arm\nxp\nxp_k6x.dtsi:397 */
		ftm1: ftm@40039000 {
			compatible = "nxp,ftm";    /* in zephyr\dts\arm\nxp\nxp_k6x.dtsi:398 */
			reg = < 0x40039000 0x98 >; /* in zephyr\dts\arm\nxp\nxp_k6x.dtsi:399 */
			interrupts = < 0x2b 0x0 >; /* in zephyr\dts\arm\nxp\nxp_k6x.dtsi:400 */
			clocks = < &mcg 0x0 >;     /* in zephyr\dts\arm\nxp\nxp_k6x.dtsi:401 */
			prescaler = < 0x10 >;      /* in zephyr\dts\arm\nxp\nxp_k6x.dtsi:402 */
			status = "disabled";       /* in zephyr\dts\arm\nxp\nxp_k6x.dtsi:403 */
		};

		/* node '/soc/ftm@4003a000' defined in zephyr\dts\arm\nxp\nxp_k6x.dtsi:406 */
		ftm2: ftm@4003a000 {
			compatible = "nxp,ftm";    /* in zephyr\dts\arm\nxp\nxp_k6x.dtsi:407 */
			reg = < 0x4003a000 0x98 >; /* in zephyr\dts\arm\nxp\nxp_k6x.dtsi:408 */
			interrupts = < 0x2c 0x0 >; /* in zephyr\dts\arm\nxp\nxp_k6x.dtsi:409 */
			clocks = < &mcg 0x0 >;     /* in zephyr\dts\arm\nxp\nxp_k6x.dtsi:410 */
			prescaler = < 0x10 >;      /* in zephyr\dts\arm\nxp\nxp_k6x.dtsi:411 */
			status = "disabled";       /* in zephyr\dts\arm\nxp\nxp_k6x.dtsi:412 */
		};

		/* node '/soc/ftm@400b9000' defined in zephyr\dts\arm\nxp\nxp_k6x.dtsi:415 */
		ftm3: ftm@400b9000 {
			reg = < 0x400b9000 0x98 >;     /* in zephyr\dts\arm\nxp\nxp_k6x.dtsi:417 */
			interrupts = < 0x47 0x0 >;     /* in zephyr\dts\arm\nxp\nxp_k6x.dtsi:418 */
			clocks = < &mcg 0x0 >;         /* in zephyr\dts\arm\nxp\nxp_k6x.dtsi:419 */
			prescaler = < 0x10 >;          /* in zephyr\dts\arm\nxp\nxp_k6x.dtsi:420 */
			status = "okay";               /* in zephyr\boards\nxp\frdm_k64f\frdm_k64f.dts:183 */
			compatible = "nxp,ftm-pwm";    /* in zephyr\boards\nxp\frdm_k64f\frdm_k64f.dts:184 */
			#pwm-cells = < 0x3 >;          /* in zephyr\boards\nxp\frdm_k64f\frdm_k64f.dts:185 */
			pinctrl-0 = < &ftm3_default >; /* in zephyr\boards\nxp\frdm_k64f\frdm_k64f.dts:186 */
			pinctrl-names = "default";     /* in zephyr\boards\nxp\frdm_k64f\frdm_k64f.dts:187 */
			clock-source = "fixed";        /* in zephyr\boards\nxp\frdm_k64f\frdm_k64f.dts:188 */
		};

		/* node '/soc/adc@4003b000' defined in zephyr\dts\arm\nxp\nxp_k6x.dtsi:424 */
		adc0: adc@4003b000 {
			compatible = "nxp,kinetis-adc16"; /* in zephyr\dts\arm\nxp\nxp_k6x.dtsi:425 */
			reg = < 0x4003b000 0x70 >;        /* in zephyr\dts\arm\nxp\nxp_k6x.dtsi:426 */
			clocks = < &sim 0x7 0x0 0xf >,
			         < &sim 0x7 0x7 0x80 >;   /* in zephyr\dts\arm\nxp\nxp_k6x.dtsi:427 */
			dmas = < &edma0 0x0 0x28 >;       /* in zephyr\dts\arm\nxp\nxp_k6x.dtsi:429 */
			dma-names = "adc0";               /* in zephyr\dts\arm\nxp\nxp_k6x.dtsi:430 */
			clk-source = < 0x0 >;             /* in zephyr\dts\arm\nxp\nxp_k6x.dtsi:431 */
			interrupts = < 0x27 0x0 >;        /* in zephyr\dts\arm\nxp\nxp_k6x.dtsi:432 */
			#io-channel-cells = < 0x1 >;      /* in zephyr\dts\arm\nxp\nxp_k6x.dtsi:434 */
			pinctrl-0 = < &adc0_default >;    /* in zephyr\boards\nxp\frdm_k64f\frdm_k64f.dts:116 */
			pinctrl-names = "default";        /* in zephyr\boards\nxp\frdm_k64f\frdm_k64f.dts:117 */
			status = "okay";                  /* in ..\nokia_lcd_zephyr\boards\frdm_k64f.overlay:61 */
			phandle = < 0x15 >;               /* in ..\nokia_lcd_zephyr\boards\frdm_k64f.overlay:67 */

			/* node '/soc/adc@4003b000/lm35' defined in ..\nokia_lcd_zephyr\boards\frdm_k64f.overlay:63 */
			lm35_sensor: lm35 {
				compatible = "lm35";               /* in ..\nokia_lcd_zephyr\boards\frdm_k64f.overlay:64 */
				io-channels = < &adc0 0x6 >;       /* in ..\nokia_lcd_zephyr\boards\frdm_k64f.overlay:67 */
				status = "okay";                   /* in ..\nokia_lcd_zephyr\boards\frdm_k64f.overlay:69 */
				label = "LM35 Temperature Sensor"; /* in ..\nokia_lcd_zephyr\boards\frdm_k64f.overlay:70 */
			};
		};

		/* node '/soc/adc@400bb000' defined in zephyr\dts\arm\nxp\nxp_k6x.dtsi:437 */
		adc1: adc@400bb000 {
			compatible = "nxp,kinetis-adc16"; /* in zephyr\dts\arm\nxp\nxp_k6x.dtsi:438 */
			reg = < 0x400bb000 0x70 >;        /* in zephyr\dts\arm\nxp\nxp_k6x.dtsi:439 */
			clocks = < &sim 0x7 0x8 0xf00 >,
			         < &sim 0x7 0xf 0x8000 >; /* in zephyr\dts\arm\nxp\nxp_k6x.dtsi:440 */
			dmas = < &edma0 0x0 0x29 >;       /* in zephyr\dts\arm\nxp\nxp_k6x.dtsi:442 */
			dma-names = "adc1";               /* in zephyr\dts\arm\nxp\nxp_k6x.dtsi:443 */
			clk-source = < 0x0 >;             /* in zephyr\dts\arm\nxp\nxp_k6x.dtsi:444 */
			interrupts = < 0x49 0x0 >;        /* in zephyr\dts\arm\nxp\nxp_k6x.dtsi:445 */
			#io-channel-cells = < 0x1 >;      /* in zephyr\dts\arm\nxp\nxp_k6x.dtsi:447 */
			status = "okay";                  /* in zephyr\boards\nxp\frdm_k64f\frdm_k64f.dts:121 */
			pinctrl-0 = < &adc1_default >;    /* in zephyr\boards\nxp\frdm_k64f\frdm_k64f.dts:122 */
			pinctrl-names = "default";        /* in zephyr\boards\nxp\frdm_k64f\frdm_k64f.dts:123 */
			phandle = < 0x1e >;               /* in zephyr\dts\arm\nxp\nxp_k6x.dtsi:65 */
		};

		/* node '/soc/dac@400cc000' defined in zephyr\dts\arm\nxp\nxp_k6x.dtsi:450 */
		dac0: dac@400cc000 {
			compatible = "nxp,kinetis-dac"; /* in zephyr\dts\arm\nxp\nxp_k6x.dtsi:451 */
			reg = < 0x400cc000 0x1000 >;    /* in zephyr\dts\arm\nxp\nxp_k6x.dtsi:452 */
			interrupts = < 0x38 0x0 >;      /* in zephyr\dts\arm\nxp\nxp_k6x.dtsi:453 */
			#io-channel-cells = < 0x1 >;    /* in zephyr\dts\arm\nxp\nxp_k6x.dtsi:456 */
			status = "okay";                /* in zephyr\boards\nxp\frdm_k64f\frdm_k64f.dts:131 */
			voltage-reference = < 0x2 >;    /* in zephyr\boards\nxp\frdm_k64f\frdm_k64f.dts:132 */
		};

		/* node '/soc/dac@400cd000' defined in zephyr\dts\arm\nxp\nxp_k6x.dtsi:459 */
		dac1: dac@400cd000 {
			compatible = "nxp,kinetis-dac"; /* in zephyr\dts\arm\nxp\nxp_k6x.dtsi:460 */
			reg = < 0x400cd000 0x1000 >;    /* in zephyr\dts\arm\nxp\nxp_k6x.dtsi:461 */
			interrupts = < 0x48 0x0 >;      /* in zephyr\dts\arm\nxp\nxp_k6x.dtsi:462 */
			voltage-reference = < 0x1 >;    /* in zephyr\dts\arm\nxp\nxp_k6x.dtsi:463 */
			status = "disabled";            /* in zephyr\dts\arm\nxp\nxp_k6x.dtsi:464 */
			#io-channel-cells = < 0x1 >;    /* in zephyr\dts\arm\nxp\nxp_k6x.dtsi:465 */
		};

		/* node '/soc/usbd@40072000' defined in zephyr\dts\arm\nxp\nxp_k6x.dtsi:468 */
		usbotg: zephyr_udc0: usbd@40072000 {
			reg = < 0x40072000 0x1000 >;     /* in zephyr\dts\arm\nxp\nxp_k6x.dtsi:470 */
			interrupts = < 0x35 0x1 >;       /* in zephyr\dts\arm\nxp\nxp_k6x.dtsi:471 */
			interrupt-names = "usb_otg";     /* in zephyr\dts\arm\nxp\nxp_k6x.dtsi:472 */
			compatible = "nxp,kinetis-usbd"; /* in zephyr\boards\nxp\frdm_k64f\frdm_k64f.dts:204 */
			status = "okay";                 /* in zephyr\boards\nxp\frdm_k64f\frdm_k64f.dts:205 */
			num-bidir-endpoints = < 0x8 >;   /* in zephyr\boards\nxp\frdm_k64f\frdm_k64f.dts:206 */
		};

		/* node '/soc/ethernet@400c0000' defined in zephyr\dts\arm\nxp\nxp_k6x.dtsi:477 */
		enet: ethernet@400c0000 {
			compatible = "nxp,enet";          /* in zephyr\dts\arm\nxp\nxp_k6x.dtsi:478 */
			reg = < 0x400c0000 0x620 >;       /* in zephyr\dts\arm\nxp\nxp_k6x.dtsi:479 */
			clocks = < &sim 0x10e1 0x0 0x0 >; /* in zephyr\dts\arm\nxp\nxp_k6x.dtsi:480 */

			/* node '/soc/ethernet@400c0000/ethernet' defined in zephyr\dts\arm\nxp\nxp_k6x.dtsi:481 */
			enet_mac: ethernet {
				compatible = "nxp,enet-mac";     /* in zephyr\dts\arm\nxp\nxp_k6x.dtsi:482 */
				interrupts = < 0x53 0x0 >,
				             < 0x54 0x0 >,
				             < 0x55 0x0 >;       /* in zephyr\dts\arm\nxp\nxp_k6x.dtsi:483 */
				interrupt-names = "TX",
				                  "RX",
				                  "ERR";         /* in zephyr\dts\arm\nxp\nxp_k6x.dtsi:484 */
				nxp,mdio = < &enet_mdio >;       /* in zephyr\dts\arm\nxp\nxp_k6x.dtsi:485 */
				ptp-clock = < &enet_ptp_clock >; /* in zephyr\dts\arm\nxp\nxp_k6x.dtsi:486 */
				status = "okay";                 /* in zephyr\boards\nxp\frdm_k64f\frdm_k64f.dts:261 */
				pinctrl-0 = < &pinmux_enet >;    /* in zephyr\boards\nxp\frdm_k64f\frdm_k64f.dts:262 */
				pinctrl-names = "default";       /* in zephyr\boards\nxp\frdm_k64f\frdm_k64f.dts:263 */
				phy-handle = < &phy >;           /* in zephyr\boards\nxp\frdm_k64f\frdm_k64f.dts:264 */
				zephyr,random-mac-address;       /* in zephyr\boards\nxp\frdm_k64f\frdm_k64f.dts:265 */
				phy-connection-type = "rmii";    /* in zephyr\boards\nxp\frdm_k64f\frdm_k64f.dts:266 */
			};

			/* node '/soc/ethernet@400c0000/mdio' defined in zephyr\dts\arm\nxp\nxp_k6x.dtsi:490 */
			enet_mdio: mdio {
				compatible = "nxp,enet-mdio";      /* in zephyr\dts\arm\nxp\nxp_k6x.dtsi:491 */
				#address-cells = < 0x1 >;          /* in zephyr\dts\arm\nxp\nxp_k6x.dtsi:493 */
				#size-cells = < 0x0 >;             /* in zephyr\dts\arm\nxp\nxp_k6x.dtsi:494 */
				status = "okay";                   /* in zephyr\boards\nxp\frdm_k64f\frdm_k64f.dts:271 */
				pinctrl-0 = < &pinmux_enet_mdio >; /* in zephyr\boards\nxp\frdm_k64f\frdm_k64f.dts:272 */
				pinctrl-names = "default";         /* in zephyr\boards\nxp\frdm_k64f\frdm_k64f.dts:273 */
				phandle = < 0x17 >;                /* in zephyr\dts\arm\nxp\nxp_k6x.dtsi:485 */

				/* node '/soc/ethernet@400c0000/mdio/phy@0' defined in zephyr\boards\nxp\frdm_k64f\frdm_k64f.dts:274 */
				phy: phy@0 {
					compatible = "microchip,ksz8081";        /* in zephyr\boards\nxp\frdm_k64f\frdm_k64f.dts:275 */
					reg = < 0x0 >;                           /* in zephyr\boards\nxp\frdm_k64f\frdm_k64f.dts:276 */
					status = "okay";                         /* in zephyr\boards\nxp\frdm_k64f\frdm_k64f.dts:277 */
					microchip,interface-type = "rmii-25MHz"; /* in zephyr\boards\nxp\frdm_k64f\frdm_k64f.dts:278 */
					phandle = < 0x1a >;                      /* in zephyr\boards\nxp\frdm_k64f\frdm_k64f.dts:264 */
				};
			};

			/* node '/soc/ethernet@400c0000/ptp_clock' defined in zephyr\dts\arm\nxp\nxp_k6x.dtsi:496 */
			enet_ptp_clock: ptp_clock {
				compatible = "nxp,enet-ptp-clock"; /* in zephyr\dts\arm\nxp\nxp_k6x.dtsi:497 */
				interrupts = < 0x52 0x0 >;         /* in zephyr\dts\arm\nxp\nxp_k6x.dtsi:498 */
				interrupt-names = "IEEE1588_TMR";  /* in zephyr\dts\arm\nxp\nxp_k6x.dtsi:499 */
				clocks = < &sim 0x10e2 0x0 0x0 >;  /* in zephyr\dts\arm\nxp\nxp_k6x.dtsi:500 */
				status = "okay";                   /* in zephyr\boards\nxp\frdm_k64f\frdm_k64f.dts:283 */
				pinctrl-0 = < &pinmux_ptp >;       /* in zephyr\boards\nxp\frdm_k64f\frdm_k64f.dts:284 */
				pinctrl-names = "default";         /* in zephyr\boards\nxp\frdm_k64f\frdm_k64f.dts:285 */
				phandle = < 0x18 >;                /* in zephyr\dts\arm\nxp\nxp_k6x.dtsi:486 */
			};
		};

		/* node '/soc/random@40029000' defined in zephyr\dts\arm\nxp\nxp_k6x.dtsi:505 */
		rnga: random@40029000 {
			compatible = "nxp,kinetis-rnga"; /* in zephyr\dts\arm\nxp\nxp_k6x.dtsi:506 */
			reg = < 0x40029000 0x1000 >;     /* in zephyr\dts\arm\nxp\nxp_k6x.dtsi:507 */
			status = "okay";                 /* in zephyr\dts\arm\nxp\nxp_k6x.dtsi:508 */
			interrupts = < 0x17 0x0 >;       /* in zephyr\dts\arm\nxp\nxp_k6x.dtsi:509 */
		};

		/* node '/soc/can@40024000' defined in zephyr\dts\arm\nxp\nxp_k6x.dtsi:512 */
		flexcan0: can@40024000 {
			compatible = "nxp,flexcan";        /* in zephyr\dts\arm\nxp\nxp_k6x.dtsi:513 */
			reg = < 0x40024000 0x1000 >;       /* in zephyr\dts\arm\nxp\nxp_k6x.dtsi:514 */
			interrupts = < 0x4b 0x0 >,
			             < 0x4c 0x0 >,
			             < 0x4d 0x0 >,
			             < 0x4e 0x0 >,
			             < 0x4f 0x0 >,
			             < 0x50 0x0 >;         /* in zephyr\dts\arm\nxp\nxp_k6x.dtsi:515 */
			interrupt-names = "mb-0-15",
			                  "bus-off",
			                  "error",
			                  "tx-warning",
			                  "rx-warning",
			                  "wake-up";       /* in zephyr\dts\arm\nxp\nxp_k6x.dtsi:516 */
			clocks = < &sim 0x2 0x103c 0x4 >;  /* in zephyr\dts\arm\nxp\nxp_k6x.dtsi:517 */
			clk-source = < 0x1 >;              /* in zephyr\dts\arm\nxp\nxp_k6x.dtsi:518 */
			status = "okay";                   /* in zephyr\boards\nxp\frdm_k64f\frdm_k64f.dts:289 */
			pinctrl-0 = < &flexcan0_default >; /* in zephyr\boards\nxp\frdm_k64f\frdm_k64f.dts:290 */
			pinctrl-names = "default";         /* in zephyr\boards\nxp\frdm_k64f\frdm_k64f.dts:291 */
		};

		/* node '/soc/dma-controller@40008000' defined in zephyr\dts\arm\nxp\nxp_k6x.dtsi:522 */
		edma0: dma-controller@40008000 {
			#dma-cells = < 0x2 >;             /* in zephyr\dts\arm\nxp\nxp_k6x.dtsi:523 */
			compatible = "nxp,mcux-edma";     /* in zephyr\dts\arm\nxp\nxp_k6x.dtsi:524 */
			nxp,version = < 0x2 >;            /* in zephyr\dts\arm\nxp\nxp_k6x.dtsi:525 */
			dma-channels = < 0x10 >;          /* in zephyr\dts\arm\nxp\nxp_k6x.dtsi:526 */
			dma-requests = < 0x40 >;          /* in zephyr\dts\arm\nxp\nxp_k6x.dtsi:527 */
			nxp,mem2mem;                      /* in zephyr\dts\arm\nxp\nxp_k6x.dtsi:528 */
			reg = < 0x40008000 0x1000 >,
			      < 0x40021000 0x1000 >;      /* in zephyr\dts\arm\nxp\nxp_k6x.dtsi:529 */
			interrupts = < 0x0 0x0 >,
			             < 0x1 0x0 >,
			             < 0x2 0x0 >,
			             < 0x3 0x0 >,
			             < 0x4 0x0 >,
			             < 0x5 0x0 >,
			             < 0x6 0x0 >,
			             < 0x7 0x0 >,
			             < 0x8 0x0 >,
			             < 0x9 0x0 >,
			             < 0xa 0x0 >,
			             < 0xb 0x0 >,
			             < 0xc 0x0 >,
			             < 0xd 0x0 >,
			             < 0xe 0x0 >,
			             < 0xf 0x0 >,
			             < 0x10 0x0 >;        /* in zephyr\dts\arm\nxp\nxp_k6x.dtsi:531 */
			clocks = < &sim 0x0 0x1040 0x2 >,
			         < &sim 0x2 0x103c 0x2 >; /* in zephyr\dts\arm\nxp\nxp_k6x.dtsi:536 */
			status = "okay";                  /* in zephyr\boards\nxp\frdm_k64f\frdm_k64f.dts:295 */
			phandle = < 0xe >;                /* in zephyr\dts\arm\nxp\nxp_k6x.dtsi:341 */
		};

		/* node '/soc/pit@40037000' defined in zephyr\dts\arm\nxp\nxp_k6x.dtsi:541 */
		pit0: pit@40037000 {
			compatible = "nxp,pit";            /* in zephyr\dts\arm\nxp\nxp_k6x.dtsi:542 */
			reg = < 0x40037000 0x1000 >;       /* in zephyr\dts\arm\nxp\nxp_k6x.dtsi:543 */
			clocks = < &sim 0x2 0x103c 0x17 >; /* in zephyr\dts\arm\nxp\nxp_k6x.dtsi:544 */
			max-load-value = < 0xffffffff >;   /* in zephyr\dts\arm\nxp\nxp_k6x.dtsi:546 */
			#address-cells = < 0x1 >;          /* in zephyr\dts\arm\nxp\nxp_k6x.dtsi:547 */
			#size-cells = < 0x0 >;             /* in zephyr\dts\arm\nxp\nxp_k6x.dtsi:548 */
			status = "okay";                   /* in zephyr\boards\nxp\frdm_k64f\frdm_k64f.dts:299 */

			/* node '/soc/pit@40037000/pit0_channel@0' defined in zephyr\dts\arm\nxp\nxp_k6x.dtsi:550 */
			pit0_channel0: pit0_channel@0 {
				compatible = "nxp,pit-channel"; /* in zephyr\dts\arm\nxp\nxp_k6x.dtsi:551 */
				reg = < 0x0 >;                  /* in zephyr\dts\arm\nxp\nxp_k6x.dtsi:552 */
				interrupts = < 0x30 0x0 >;      /* in zephyr\dts\arm\nxp\nxp_k6x.dtsi:553 */
				status = "disabled";            /* in zephyr\dts\arm\nxp\nxp_k6x.dtsi:554 */
			};

			/* node '/soc/pit@40037000/pit0_channel@1' defined in zephyr\dts\arm\nxp\nxp_k6x.dtsi:557 */
			pit0_channel1: pit0_channel@1 {
				compatible = "nxp,pit-channel"; /* in zephyr\dts\arm\nxp\nxp_k6x.dtsi:558 */
				reg = < 0x1 >;                  /* in zephyr\dts\arm\nxp\nxp_k6x.dtsi:559 */
				interrupts = < 0x31 0x0 >;      /* in zephyr\dts\arm\nxp\nxp_k6x.dtsi:560 */
				status = "disabled";            /* in zephyr\dts\arm\nxp\nxp_k6x.dtsi:561 */
			};

			/* node '/soc/pit@40037000/pit0_channel@2' defined in zephyr\dts\arm\nxp\nxp_k6x.dtsi:564 */
			pit0_channel2: pit0_channel@2 {
				compatible = "nxp,pit-channel"; /* in zephyr\dts\arm\nxp\nxp_k6x.dtsi:565 */
				reg = < 0x2 >;                  /* in zephyr\dts\arm\nxp\nxp_k6x.dtsi:566 */
				interrupts = < 0x32 0x0 >;      /* in zephyr\dts\arm\nxp\nxp_k6x.dtsi:567 */
				status = "disabled";            /* in zephyr\dts\arm\nxp\nxp_k6x.dtsi:568 */
			};

			/* node '/soc/pit@40037000/pit0_channel@3' defined in zephyr\dts\arm\nxp\nxp_k6x.dtsi:571 */
			pit0_channel3: pit0_channel@3 {
				compatible = "nxp,pit-channel"; /* in zephyr\dts\arm\nxp\nxp_k6x.dtsi:572 */
				reg = < 0x3 >;                  /* in zephyr\dts\arm\nxp\nxp_k6x.dtsi:573 */
				interrupts = < 0x33 0x0 >;      /* in zephyr\dts\arm\nxp\nxp_k6x.dtsi:574 */
				status = "disabled";            /* in zephyr\dts\arm\nxp\nxp_k6x.dtsi:575 */
			};
		};
	};

	/* node '/cpus' defined in zephyr\dts\arm\nxp\nxp_k6x.dtsi:21 */
	cpus {
		#address-cells = < 0x1 >; /* in zephyr\dts\arm\nxp\nxp_k6x.dtsi:22 */
		#size-cells = < 0x0 >;    /* in zephyr\dts\arm\nxp\nxp_k6x.dtsi:23 */

		/* node '/cpus/cpu@0' defined in zephyr\dts\arm\nxp\nxp_k6x.dtsi:25 */
		cpu0: cpu@0 {
			device_type = "cpu";             /* in zephyr\dts\arm\nxp\nxp_k6x.dtsi:26 */
			compatible = "arm,cortex-m4f";   /* in zephyr\dts\arm\nxp\nxp_k6x.dtsi:27 */
			reg = < 0x0 >;                   /* in zephyr\dts\arm\nxp\nxp_k6x.dtsi:28 */
			clock-frequency = < 0x7270e00 >; /* in zephyr\boards\nxp\frdm_k64f\frdm_k64f.dts:111 */
		};
	};

	/* node '/memory@1fff0000' defined in zephyr\dts\arm\nxp\nxp_k6x.dtsi:41 */
	sram_l: memory@1fff0000 {
		compatible = "zephyr,memory-region",
		             "mmio-sram";            /* in zephyr\dts\arm\nxp\nxp_k6x.dtsi:42 */
		reg = < 0x1fff0000 0x10000 >;        /* in zephyr\dts\arm\nxp\nxp_k6x.dtsi:43 */
		zephyr,memory-region = "SRAML";      /* in zephyr\dts\arm\nxp\nxp_k6x.dtsi:44 */
	};

	/* node '/memory@20000000' defined in zephyr\dts\arm\nxp\nxp_k6x.dtsi:47 */
	sram0: memory@20000000 {
		compatible = "mmio-sram";     /* in zephyr\dts\arm\nxp\nxp_k6x.dtsi:48 */
		reg = < 0x20000000 0x30000 >; /* in zephyr\dts\arm\nxp\nxp_k6x.dtsi:49 */
	};

	/* node '/temp0' defined in zephyr\dts\arm\nxp\nxp_k6x.dtsi:52 */
	temp0: temp0 {
		compatible = "nxp,kinetis-temperature"; /* in zephyr\dts\arm\nxp\nxp_k6x.dtsi:53 */
		io-channels = < &adc0 0x1a >,
		              < &adc0 0x1b >;           /* in zephyr\dts\arm\nxp\nxp_k6x.dtsi:54 */
		io-channel-names = "SENSOR",
		                   "BANDGAP";           /* in zephyr\dts\arm\nxp\nxp_k6x.dtsi:55 */
		bandgap-voltage = < 0xf4240 >;          /* in zephyr\dts\arm\nxp\nxp_k6x.dtsi:56 */
		vtemp25 = < 0xaece0 >;                  /* in zephyr\dts\arm\nxp\nxp_k6x.dtsi:57 */
		sensor-slope-cold = < 0x654 >;          /* in zephyr\dts\arm\nxp\nxp_k6x.dtsi:58 */
		sensor-slope-hot = < 0x654 >;           /* in zephyr\dts\arm\nxp\nxp_k6x.dtsi:59 */
		status = "disabled";                    /* in zephyr\dts\arm\nxp\nxp_k6x.dtsi:60 */
	};

	/* node '/temp1' defined in zephyr\dts\arm\nxp\nxp_k6x.dtsi:63 */
	temp1: temp1 {
		compatible = "nxp,kinetis-temperature"; /* in zephyr\dts\arm\nxp\nxp_k6x.dtsi:64 */
		io-channels = < &adc1 0x1a >,
		              < &adc1 0x1b >;           /* in zephyr\dts\arm\nxp\nxp_k6x.dtsi:65 */
		io-channel-names = "SENSOR",
		                   "BANDGAP";           /* in zephyr\dts\arm\nxp\nxp_k6x.dtsi:66 */
		bandgap-voltage = < 0xf4240 >;          /* in zephyr\dts\arm\nxp\nxp_k6x.dtsi:67 */
		vtemp25 = < 0xaece0 >;                  /* in zephyr\dts\arm\nxp\nxp_k6x.dtsi:68 */
		sensor-slope-cold = < 0x654 >;          /* in zephyr\dts\arm\nxp\nxp_k6x.dtsi:69 */
		sensor-slope-hot = < 0x654 >;           /* in zephyr\dts\arm\nxp\nxp_k6x.dtsi:70 */
		status = "okay";                        /* in zephyr\boards\nxp\frdm_k64f\frdm_k64f.dts:127 */
	};

	/* node '/pinctrl' defined in zephyr\dts\arm\nxp\nxp_k6x.dtsi:76 */
	pinctrl: pinctrl {
		compatible = "nxp,port-pinctrl"; /* in zephyr\dts\arm\nxp\nxp_k6x.dtsi:77 */
		status = "okay";                 /* in zephyr\dts\arm\nxp\nxp_k6x.dtsi:78 */

		/* node '/pinctrl/adc0_default' defined in zephyr\boards\nxp\frdm_k64f\frdm_k64f-pinctrl.dtsi:13 */
		adc0_default: adc0_default {
			phandle = < 0x14 >; /* in zephyr\boards\nxp\frdm_k64f\frdm_k64f.dts:116 */

			/* node '/pinctrl/adc0_default/group0' defined in zephyr\boards\nxp\frdm_k64f\frdm_k64f-pinctrl.dtsi:14 */
			group0 {
				pinmux = < 0x20000000 >; /* in zephyr\boards\nxp\frdm_k64f\frdm_k64f-pinctrl.dtsi:15 */
				drive-strength = "low";  /* in zephyr\boards\nxp\frdm_k64f\frdm_k64f-pinctrl.dtsi:16 */
				slew-rate = "fast";      /* in zephyr\boards\nxp\frdm_k64f\frdm_k64f-pinctrl.dtsi:17 */
			};
		};

		/* node '/pinctrl/adc1_default' defined in zephyr\boards\nxp\frdm_k64f\frdm_k64f-pinctrl.dtsi:21 */
		adc1_default: adc1_default {
			phandle = < 0x16 >; /* in zephyr\boards\nxp\frdm_k64f\frdm_k64f.dts:122 */

			/* node '/pinctrl/adc1_default/group0' defined in zephyr\boards\nxp\frdm_k64f\frdm_k64f-pinctrl.dtsi:22 */
			group0 {
				pinmux = < 0x12800000 >; /* in zephyr\boards\nxp\frdm_k64f\frdm_k64f-pinctrl.dtsi:23 */
				drive-strength = "low";  /* in zephyr\boards\nxp\frdm_k64f\frdm_k64f-pinctrl.dtsi:24 */
				slew-rate = "fast";      /* in zephyr\boards\nxp\frdm_k64f\frdm_k64f-pinctrl.dtsi:25 */
			};
		};

		/* node '/pinctrl/pinmux_enet' defined in zephyr\boards\nxp\frdm_k64f\frdm_k64f-pinctrl.dtsi:29 */
		pinmux_enet: pinmux_enet {
			phandle = < 0x19 >; /* in zephyr\boards\nxp\frdm_k64f\frdm_k64f.dts:262 */

			/* node '/pinctrl/pinmux_enet/group1' defined in zephyr\boards\nxp\frdm_k64f\frdm_k64f-pinctrl.dtsi:30 */
			group1 {
				pinmux = < 0x1400400 >,
				         < 0x3000400 >,
				         < 0x3400400 >,
				         < 0x3800400 >,
				         < 0x3c00400 >,
				         < 0x4000400 >,
				         < 0x4400400 >; /* in zephyr\boards\nxp\frdm_k64f\frdm_k64f-pinctrl.dtsi:31 */
				drive-strength = "low"; /* in zephyr\boards\nxp\frdm_k64f\frdm_k64f-pinctrl.dtsi:38 */
				slew-rate = "fast";     /* in zephyr\boards\nxp\frdm_k64f\frdm_k64f-pinctrl.dtsi:39 */
			};
		};

		/* node '/pinctrl/pinmux_enet_mdio' defined in zephyr\boards\nxp\frdm_k64f\frdm_k64f-pinctrl.dtsi:43 */
		pinmux_enet_mdio: pinmux_enet_mdio {
			phandle = < 0x1b >; /* in zephyr\boards\nxp\frdm_k64f\frdm_k64f.dts:272 */

			/* node '/pinctrl/pinmux_enet_mdio/group0' defined in zephyr\boards\nxp\frdm_k64f\frdm_k64f-pinctrl.dtsi:44 */
			group0 {
				pinmux = < 0x10000400 >; /* in zephyr\boards\nxp\frdm_k64f\frdm_k64f-pinctrl.dtsi:45 */
				drive-strength = "low";  /* in zephyr\boards\nxp\frdm_k64f\frdm_k64f-pinctrl.dtsi:46 */
				drive-open-drain;        /* in zephyr\boards\nxp\frdm_k64f\frdm_k64f-pinctrl.dtsi:47 */
				bias-pull-up;            /* in zephyr\boards\nxp\frdm_k64f\frdm_k64f-pinctrl.dtsi:48 */
				slew-rate = "fast";      /* in zephyr\boards\nxp\frdm_k64f\frdm_k64f-pinctrl.dtsi:49 */
			};

			/* node '/pinctrl/pinmux_enet_mdio/group1' defined in zephyr\boards\nxp\frdm_k64f\frdm_k64f-pinctrl.dtsi:51 */
			group1 {
				pinmux = < 0x10400400 >; /* in zephyr\boards\nxp\frdm_k64f\frdm_k64f-pinctrl.dtsi:52 */
				drive-strength = "low";  /* in zephyr\boards\nxp\frdm_k64f\frdm_k64f-pinctrl.dtsi:53 */
				slew-rate = "fast";      /* in zephyr\boards\nxp\frdm_k64f\frdm_k64f-pinctrl.dtsi:54 */
			};
		};

		/* node '/pinctrl/pinmux_ptp' defined in zephyr\boards\nxp\frdm_k64f\frdm_k64f-pinctrl.dtsi:58 */
		pinmux_ptp: pinmux_ptp {
			phandle = < 0x1c >; /* in zephyr\boards\nxp\frdm_k64f\frdm_k64f.dts:284 */

			/* node '/pinctrl/pinmux_ptp/group0' defined in zephyr\boards\nxp\frdm_k64f\frdm_k64f-pinctrl.dtsi:59 */
			group0 {
				pinmux = < 0x24000400 >,
				         < 0x24400400 >,
				         < 0x24800400 >; /* in zephyr\boards\nxp\frdm_k64f\frdm_k64f-pinctrl.dtsi:60 */
				drive-strength = "low";  /* in zephyr\boards\nxp\frdm_k64f\frdm_k64f-pinctrl.dtsi:63 */
				slew-rate = "fast";      /* in zephyr\boards\nxp\frdm_k64f\frdm_k64f-pinctrl.dtsi:64 */
			};
		};

		/* node '/pinctrl/flexcan0_default' defined in zephyr\boards\nxp\frdm_k64f\frdm_k64f-pinctrl.dtsi:68 */
		flexcan0_default: flexcan0_default {
			phandle = < 0x1d >; /* in zephyr\boards\nxp\frdm_k64f\frdm_k64f.dts:290 */

			/* node '/pinctrl/flexcan0_default/group0' defined in zephyr\boards\nxp\frdm_k64f\frdm_k64f-pinctrl.dtsi:69 */
			group0 {
				pinmux = < 0x14c00200 >; /* in zephyr\boards\nxp\frdm_k64f\frdm_k64f-pinctrl.dtsi:70 */
				drive-strength = "low";  /* in zephyr\boards\nxp\frdm_k64f\frdm_k64f-pinctrl.dtsi:71 */
				bias-pull-up;            /* in zephyr\boards\nxp\frdm_k64f\frdm_k64f-pinctrl.dtsi:72 */
				slew-rate = "fast";      /* in zephyr\boards\nxp\frdm_k64f\frdm_k64f-pinctrl.dtsi:73 */
			};

			/* node '/pinctrl/flexcan0_default/group1' defined in zephyr\boards\nxp\frdm_k64f\frdm_k64f-pinctrl.dtsi:75 */
			group1 {
				pinmux = < 0x14800200 >; /* in zephyr\boards\nxp\frdm_k64f\frdm_k64f-pinctrl.dtsi:76 */
				drive-strength = "low";  /* in zephyr\boards\nxp\frdm_k64f\frdm_k64f-pinctrl.dtsi:77 */
				slew-rate = "fast";      /* in zephyr\boards\nxp\frdm_k64f\frdm_k64f-pinctrl.dtsi:78 */
			};
		};

		/* node '/pinctrl/ftm0_default' defined in zephyr\boards\nxp\frdm_k64f\frdm_k64f-pinctrl.dtsi:82 */
		ftm0_default: ftm0_default {
			phandle = < 0x12 >; /* in zephyr\boards\nxp\frdm_k64f\frdm_k64f.dts:177 */

			/* node '/pinctrl/ftm0_default/group0' defined in zephyr\boards\nxp\frdm_k64f\frdm_k64f-pinctrl.dtsi:83 */
			group0 {
				pinmux = < 0x20400400 >; /* in zephyr\boards\nxp\frdm_k64f\frdm_k64f-pinctrl.dtsi:84 */
				drive-strength = "low";  /* in zephyr\boards\nxp\frdm_k64f\frdm_k64f-pinctrl.dtsi:85 */
				slew-rate = "fast";      /* in zephyr\boards\nxp\frdm_k64f\frdm_k64f-pinctrl.dtsi:86 */
			};
		};

		/* node '/pinctrl/ftm3_default' defined in zephyr\boards\nxp\frdm_k64f\frdm_k64f-pinctrl.dtsi:90 */
		ftm3_default: ftm3_default {
			phandle = < 0x13 >; /* in zephyr\boards\nxp\frdm_k64f\frdm_k64f.dts:186 */

			/* node '/pinctrl/ftm3_default/group0' defined in zephyr\boards\nxp\frdm_k64f\frdm_k64f-pinctrl.dtsi:91 */
			group0 {
				pinmux = < 0x22000300 >,
				         < 0x22400300 >; /* in zephyr\boards\nxp\frdm_k64f\frdm_k64f-pinctrl.dtsi:92 */
				drive-strength = "low";  /* in zephyr\boards\nxp\frdm_k64f\frdm_k64f-pinctrl.dtsi:94 */
				slew-rate = "fast";      /* in zephyr\boards\nxp\frdm_k64f\frdm_k64f-pinctrl.dtsi:95 */
			};
		};

		/* node '/pinctrl/i2c0_default' defined in zephyr\boards\nxp\frdm_k64f\frdm_k64f-pinctrl.dtsi:99 */
		i2c0_default: i2c0_default {
			phandle = < 0x4 >; /* in ..\nokia_lcd_zephyr\boards\frdm_k64f.overlay:82 */

			/* node '/pinctrl/i2c0_default/group0' defined in zephyr\boards\nxp\frdm_k64f\frdm_k64f-pinctrl.dtsi:100 */
			group0 {
				pinmux = < 0x46000500 >,
				         < 0x46400500 >; /* in zephyr\boards\nxp\frdm_k64f\frdm_k64f-pinctrl.dtsi:101 */
				drive-strength = "low";  /* in zephyr\boards\nxp\frdm_k64f\frdm_k64f-pinctrl.dtsi:103 */
				drive-open-drain;        /* in zephyr\boards\nxp\frdm_k64f\frdm_k64f-pinctrl.dtsi:104 */
				slew-rate = "fast";      /* in zephyr\boards\nxp\frdm_k64f\frdm_k64f-pinctrl.dtsi:105 */
			};
		};

		/* node '/pinctrl/ptp_default' defined in zephyr\boards\nxp\frdm_k64f\frdm_k64f-pinctrl.dtsi:110 */
		ptp_default: ptp_default {

			/* node '/pinctrl/ptp_default/group0' defined in zephyr\boards\nxp\frdm_k64f\frdm_k64f-pinctrl.dtsi:111 */
			group0 {
				pinmux = < 0x24000400 >,
				         < 0x24400400 >,
				         < 0x24800400 >; /* in zephyr\boards\nxp\frdm_k64f\frdm_k64f-pinctrl.dtsi:112 */
				drive-strength = "low";  /* in zephyr\boards\nxp\frdm_k64f\frdm_k64f-pinctrl.dtsi:115 */
				slew-rate = "fast";      /* in zephyr\boards\nxp\frdm_k64f\frdm_k64f-pinctrl.dtsi:116 */
			};
		};

		/* node '/pinctrl/spi0_default' defined in zephyr\boards\nxp\frdm_k64f\frdm_k64f-pinctrl.dtsi:121 */
		spi0_default: spi0_default {
			phandle = < 0xf >; /* in ..\nokia_lcd_zephyr\boards\frdm_k64f.overlay:48 */

			/* node '/pinctrl/spi0_default/group0' defined in zephyr\boards\nxp\frdm_k64f\frdm_k64f-pinctrl.dtsi:122 */
			group0 {
				pinmux = < 0x30000200 >,
				         < 0x30400200 >,
				         < 0x30800200 >,
				         < 0x30c00200 >; /* in zephyr\boards\nxp\frdm_k64f\frdm_k64f-pinctrl.dtsi:123 */
				drive-strength = "low";  /* in zephyr\boards\nxp\frdm_k64f\frdm_k64f-pinctrl.dtsi:127 */
				slew-rate = "fast";      /* in zephyr\boards\nxp\frdm_k64f\frdm_k64f-pinctrl.dtsi:128 */
			};
		};

		/* node '/pinctrl/spi1_default' defined in zephyr\boards\nxp\frdm_k64f\frdm_k64f-pinctrl.dtsi:132 */
		spi1_default: spi1_default {
			phandle = < 0x10 >; /* in zephyr\boards\nxp\frdm_k64f\frdm_k64f.dts:156 */

			/* node '/pinctrl/spi1_default/group0' defined in zephyr\boards\nxp\frdm_k64f\frdm_k64f-pinctrl.dtsi:133 */
			group0 {
				pinmux = < 0x41000200 >,
				         < 0x40800200 >,
				         < 0x40c00700 >,
				         < 0x40400700 >; /* in zephyr\boards\nxp\frdm_k64f\frdm_k64f-pinctrl.dtsi:134 */
				drive-strength = "low";  /* in zephyr\boards\nxp\frdm_k64f\frdm_k64f-pinctrl.dtsi:138 */
				slew-rate = "fast";      /* in zephyr\boards\nxp\frdm_k64f\frdm_k64f-pinctrl.dtsi:139 */
			};
		};

		/* node '/pinctrl/uart0_default' defined in zephyr\boards\nxp\frdm_k64f\frdm_k64f-pinctrl.dtsi:144 */
		uart0_default: uart0_default {
			phandle = < 0x6 >; /* in zephyr\boards\nxp\frdm_k64f\frdm_k64f.dts:194 */

			/* node '/pinctrl/uart0_default/group0' defined in zephyr\boards\nxp\frdm_k64f\frdm_k64f-pinctrl.dtsi:145 */
			group0 {
				pinmux = < 0x14000300 >,
				         < 0x14400300 >; /* in zephyr\boards\nxp\frdm_k64f\frdm_k64f-pinctrl.dtsi:146 */
				drive-strength = "low";  /* in zephyr\boards\nxp\frdm_k64f\frdm_k64f-pinctrl.dtsi:148 */
				slew-rate = "fast";      /* in zephyr\boards\nxp\frdm_k64f\frdm_k64f-pinctrl.dtsi:149 */
			};
		};

		/* node '/pinctrl/uart2_default' defined in zephyr\boards\nxp\frdm_k64f\frdm_k64f-pinctrl.dtsi:154 */
		uart2_default: uart2_default {
			phandle = < 0x7 >; /* in zephyr\boards\nxp\frdm_k64f\frdm_k64f.dts:199 */

			/* node '/pinctrl/uart2_default/group0' defined in zephyr\boards\nxp\frdm_k64f\frdm_k64f-pinctrl.dtsi:155 */
			group0 {
				pinmux = < 0x30400300 >,
				         < 0x30000300 >,
				         < 0x30800300 >,
				         < 0x30c00300 >; /* in zephyr\boards\nxp\frdm_k64f\frdm_k64f-pinctrl.dtsi:156 */
				drive-strength = "low";  /* in zephyr\boards\nxp\frdm_k64f\frdm_k64f-pinctrl.dtsi:160 */
				slew-rate = "fast";      /* in zephyr\boards\nxp\frdm_k64f\frdm_k64f-pinctrl.dtsi:161 */
			};
		};

		/* node '/pinctrl/uart3_default' defined in zephyr\boards\nxp\frdm_k64f\frdm_k64f-pinctrl.dtsi:166 */
		uart3_default: uart3_default {
			phandle = < 0x8 >; /* in ..\nokia_lcd_zephyr\boards\frdm_k64f.overlay:113 */

			/* node '/pinctrl/uart3_default/group0' defined in zephyr\boards\nxp\frdm_k64f\frdm_k64f-pinctrl.dtsi:167 */
			group0 {
				pinmux = < 0x24000300 >,
				         < 0x24400300 >; /* in zephyr\boards\nxp\frdm_k64f\frdm_k64f-pinctrl.dtsi:168 */
				drive-strength = "low";  /* in zephyr\boards\nxp\frdm_k64f\frdm_k64f-pinctrl.dtsi:170 */
				slew-rate = "fast";      /* in zephyr\boards\nxp\frdm_k64f\frdm_k64f-pinctrl.dtsi:171 */
			};
		};
	};

	/* node '/leds' defined in zephyr\boards\nxp\frdm_k64f\frdm_k64f.dts:35 */
	leds {
		compatible = "gpio-leds"; /* in zephyr\boards\nxp\frdm_k64f\frdm_k64f.dts:36 */

		/* node '/leds/led_0' defined in zephyr\boards\nxp\frdm_k64f\frdm_k64f.dts:37 */
		red_led: led_0 {
			gpios = < &gpiob 0x16 0x1 >; /* in zephyr\boards\nxp\frdm_k64f\frdm_k64f.dts:38 */
			label = "User LD1";          /* in zephyr\boards\nxp\frdm_k64f\frdm_k64f.dts:39 */
		};

		/* node '/leds/led_1' defined in zephyr\boards\nxp\frdm_k64f\frdm_k64f.dts:41 */
		green_led: led_1 {
			gpios = < &gpioe 0x1a 0x1 >; /* in zephyr\boards\nxp\frdm_k64f\frdm_k64f.dts:42 */
			label = "User LD2";          /* in zephyr\boards\nxp\frdm_k64f\frdm_k64f.dts:43 */
		};

		/* node '/leds/led_2' defined in zephyr\boards\nxp\frdm_k64f\frdm_k64f.dts:45 */
		blue_led: led_2 {
			gpios = < &gpiob 0x15 0x1 >; /* in zephyr\boards\nxp\frdm_k64f\frdm_k64f.dts:46 */
			label = "User LD3";          /* in zephyr\boards\nxp\frdm_k64f\frdm_k64f.dts:47 */
		};
	};

	/* node '/gpio_keys' defined in zephyr\boards\nxp\frdm_k64f\frdm_k64f.dts:51 */
	gpio_keys {
		compatible = "gpio-keys"; /* in zephyr\boards\nxp\frdm_k64f\frdm_k64f.dts:52 */

		/* node '/gpio_keys/button_0' defined in zephyr\boards\nxp\frdm_k64f\frdm_k64f.dts:53 */
		user_button_2: button_0 {
			label = "User SW2";         /* in zephyr\boards\nxp\frdm_k64f\frdm_k64f.dts:54 */
			gpios = < &gpioc 0x6 0x1 >; /* in zephyr\boards\nxp\frdm_k64f\frdm_k64f.dts:55 */
			zephyr,code = < 0xb >;      /* in zephyr\boards\nxp\frdm_k64f\frdm_k64f.dts:56 */
		};

		/* node '/gpio_keys/button_1' defined in zephyr\boards\nxp\frdm_k64f\frdm_k64f.dts:58 */
		user_button_3: button_1 {
			label = "User SW3";         /* in zephyr\boards\nxp\frdm_k64f\frdm_k64f.dts:59 */
			gpios = < &gpioa 0x4 0x1 >; /* in zephyr\boards\nxp\frdm_k64f\frdm_k64f.dts:60 */
			zephyr,code = < 0x2 >;      /* in zephyr\boards\nxp\frdm_k64f\frdm_k64f.dts:61 */
		};
	};

	/* node '/connector' defined in zephyr\boards\nxp\frdm_k64f\frdm_k64f.dts:65 */
	arduino_header: connector {
		compatible = "arduino-header-r3";          /* in zephyr\boards\nxp\frdm_k64f\frdm_k64f.dts:66 */
		#gpio-cells = < 0x2 >;                     /* in zephyr\boards\nxp\frdm_k64f\frdm_k64f.dts:67 */
		gpio-map-mask = < 0xffffffff 0xffffffc0 >; /* in zephyr\boards\nxp\frdm_k64f\frdm_k64f.dts:68 */
		gpio-map-pass-thru = < 0x0 0x3f >;         /* in zephyr\boards\nxp\frdm_k64f\frdm_k64f.dts:69 */
		gpio-map = < 0x0 0x0 &gpiob 0x2 0x0 >,
		           < 0x1 0x0 &gpiob 0x3 0x0 >,
		           < 0x2 0x0 &gpiob 0xa 0x0 >,
		           < 0x3 0x0 &gpiob 0xb 0x0 >,
		           < 0x4 0x0 &gpioc 0xb 0x0 >,
		           < 0x5 0x0 &gpioc 0xa 0x0 >,
		           < 0x6 0x0 &gpioc 0x10 0x0 >,
		           < 0x7 0x0 &gpioc 0x11 0x0 >,
		           < 0x8 0x0 &gpiob 0x9 0x0 >,
		           < 0x9 0x0 &gpioa 0x1 0x0 >,
		           < 0xa 0x0 &gpiob 0x17 0x0 >,
		           < 0xb 0x0 &gpioa 0x2 0x0 >,
		           < 0xc 0x0 &gpioc 0x2 0x0 >,
		           < 0xd 0x0 &gpioc 0x3 0x0 >,
		           < 0xe 0x0 &gpioc 0xc 0x0 >,
		           < 0xf 0x0 &gpioc 0x4 0x0 >,
		           < 0x10 0x0 &gpiod 0x0 0x0 >,
		           < 0x11 0x0 &gpiod 0x2 0x0 >,
		           < 0x12 0x0 &gpiod 0x3 0x0 >,
		           < 0x13 0x0 &gpiod 0x1 0x0 >,
		           < 0x14 0x0 &gpioe 0x19 0x0 >,
		           < 0x15 0x0 &gpioe 0x18 0x0 >;   /* in zephyr\boards\nxp\frdm_k64f\frdm_k64f.dts:70 */
	};

	/* node '/io_pins' defined in ..\nokia_lcd_zephyr\boards\frdm_k64f.overlay:18 */
	io_pins {
		compatible = "gpio-leds"; /* in ..\nokia_lcd_zephyr\boards\frdm_k64f.overlay:19 */

		/* node '/io_pins/cmd_data' defined in ..\nokia_lcd_zephyr\boards\frdm_k64f.overlay:21 */
		cmd_data: cmd_data {
			gpios = < &gpioc 0x5 0x0 >; /* in ..\nokia_lcd_zephyr\boards\frdm_k64f.overlay:22 */
			label = "LCD Cmd_Data";     /* in ..\nokia_lcd_zephyr\boards\frdm_k64f.overlay:23 */
		};

		/* node '/io_pins/reset_sign' defined in ..\nokia_lcd_zephyr\boards\frdm_k64f.overlay:26 */
		reset_sign: reset_sign {
			gpios = < &gpioc 0x7 0x0 >; /* in ..\nokia_lcd_zephyr\boards\frdm_k64f.overlay:27 */
			label = "LCD Reset";        /* in ..\nokia_lcd_zephyr\boards\frdm_k64f.overlay:28 */
		};

		/* node '/io_pins/fan_motor' defined in ..\nokia_lcd_zephyr\boards\frdm_k64f.overlay:32 */
		fan_motor: fan_motor {
			gpios = < &gpioc 0xc 0x0 >;          /* in ..\nokia_lcd_zephyr\boards\frdm_k64f.overlay:33 */
			label = "Ventilation Motor Control"; /* in ..\nokia_lcd_zephyr\boards\frdm_k64f.overlay:34 */
		};

		/* node '/io_pins/irrigation_motor' defined in ..\nokia_lcd_zephyr\boards\frdm_k64f.overlay:37 */
		irrigation_motor: irrigation_motor {
			gpios = < &gpioc 0xd 0x0 >;         /* in ..\nokia_lcd_zephyr\boards\frdm_k64f.overlay:38 */
			label = "Irrigation Motor Control"; /* in ..\nokia_lcd_zephyr\boards\frdm_k64f.overlay:39 */
		};
	};
};
